VERSION ""

NS_ :

BS_:

BU_: AuxInput VT TECU TC Sprayer GPS

BO_ 2365458942 TFR: 8 Vector__XXX
 SG_ LimitStatusReporting : 27|1@1+ (1,0) [0|0] "" Vector__XXX
 SG_ SpeedInfo_EngineSpeed : 0|1@1+ (1,0) [0|1] "" Vector__XXX
 SG_ SpeedInfo_GroundBasedSpeed : 1|1@1+ (1,0) [0|1] "" Vector__XXX
 SG_ SpeedInfo_WheelBasedSpeed : 2|1@1+ (1,0) [0|1] "" Vector__XXX
 SG_ PowerMgt_MaintainPower : 3|1@1+ (1,0) [0|1] "" Vector__XXX
 SG_ PowerMgt_MaxTimeTractorPower : 4|1@1+ (1,0) [0|1] "" Vector__XXX
 SG_ PowerMgt_KeySwitch : 5|1@1+ (1,0) [0|1] "" Vector__XXX
 SG_ TractorClass : 6|2@1+ (1,0) [0|3] "" Vector__XXX
 SG_ LanguageCmdStorageInTractorECU : 10|1@1+ (1,0) [0|1] "" Vector__XXX
 SG_ Lighting_MinimalSet : 11|1@1+ (1,0) [0|1] "" Vector__XXX
 SG_ PTOInfo_RearShaftEngagement : 12|1@1+ (1,0) [0|0] "" Vector__XXX
 SG_ PTOInfo_RearShaftSpeed : 13|1@1+ (1,0) [0|1] "" Vector__XXX
 SG_ HitchInfo_RearInWork : 14|1@1+ (1,0) [0|1] "" Vector__XXX
 SG_ HitchInfo_RearPosition : 15|1@1+ (1,0) [0|1] "" Vector__XXX
 SG_ EstimatedOrMeasuredAuxValveState : 16|1@1+ (1,0) [0|1] "" Vector__XXX
 SG_ Light_FullImplLightingMessageSet : 17|1@1+ (1,0) [0|1] "" Vector__XXX
 SG_ AddHitchParameter_RearDraft : 18|1@1+ (1,0) [0|1] "" Vector__XXX
 SG_ SpeedAndDist_WheelBasedDirection : 19|1@1+ (1,0) [0|1] "" Vector__XXX
 SG_ SpeedAndDist_WheelBasedDistance : 20|1@1+ (1,0) [0|1] "" Vector__XXX
 SG_ SpeedAndDist_GndBasedDirection : 21|1@1+ (1,0) [0|1] "" Vector__XXX
 SG_ SpeedAndDist_GndBasedDistance : 22|1@1+ (1,0) [0|1] "" Vector__XXX
 SG_ TimeDate : 23|1@1+ (1,0) [0|1] "" Vector__XXX
 SG_ AuxiliaryValveCmd : 28|1@1+ (1,0) [0|1] "" Vector__XXX
 SG_ PTOCmd_RearPTOEngagementCmd : 29|1@1+ (1,0) [0|1] "" Vector__XXX
 SG_ PTOCmd_RearPTOSpeedCmd : 30|1@1+ (1,0) [0|1] "" Vector__XXX
 SG_ HitchCmd_RearHitchPosition : 31|1@1+ (1,0) [0|1] "" Vector__XXX
 SG_ NavigPseudorangeNoiseStatistic : 37|1@1+ (1,0) [0|1] "" Vector__XXX
 SG_ NavigSystemPositionData : 38|1@1+ (1,0) [0|1] "" Vector__XXX
 SG_ NavigSystemHighOutputPosition : 39|1@1+ (1,0) [0|1] "" Vector__XXX
 SG_ PTOCmd_FrontPTOEngagementCmd : 40|1@1+ (1,0) [0|1] "" Vector__XXX
 SG_ PTOCmd_FrontPTOSpeedCmd : 41|1@1+ (1,0) [0|1] "" Vector__XXX
 SG_ HitchCmd_FrontHitchPosition : 42|1@1+ (1,0) [0|1] "" Vector__XXX
 SG_ AddHitchParameter__FrontDraft : 43|1@1+ (1,0) [0|1] "" Vector__XXX
 SG_ PTOInfo_FrontShaftEngagement : 44|1@1+ (1,0) [0|1] "" Vector__XXX
 SG_ PTOInfo_FrontShaftSpeed : 45|1@1+ (1,0) [0|1] "" Vector__XXX
 SG_ HitchInfo_FrontInWork : 46|1@1+ (1,0) [0|1] "" Vector__XXX
 SG_ HitchInfo_FrontPosition : 47|1@1+ (1,0) [0|1] "" Vector__XXX

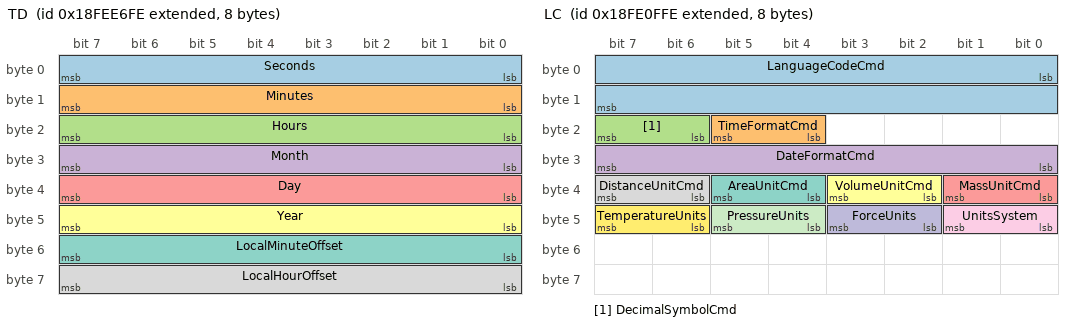
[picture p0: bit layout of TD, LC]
BO_ 2566842110 TD: 8 Vector__XXX
 SG_ Seconds : 0|8@1+ (0.25,0) [0|59.75] "s" Vector__XXX
 SG_ Minutes : 8|8@1+ (1,0) [0|59] "min" Vector__XXX
 SG_ Hours : 16|8@1+ (1,0) [0|23] "h" Vector__XXX
 SG_ Month : 24|8@1+ (1,0) [0|12] "month" Vector__XXX
 SG_ Day : 32|8@1+ (0.25,0) [0.25|31.75] "day" Vector__XXX
 SG_ Year : 40|8@1+ (1,1985) [1985|2235] "year" Vector__XXX
 SG_ LocalMinuteOffset : 48|8@1+ (1,0) [0|59] "min" Vector__XXX
 SG_ LocalHourOffset : 56|8@1+ (1,-125) [-149|-102] "" Vector__XXX

BO_ 2566787070 LC: 8 Vector__XXX
 SG_ LanguageCodeCmd : 0|16@1+ (1,0) [0|16383] "" Vector__XXX
 SG_ TimeFormatCmd : 20|2@1+ (1,0) [0|3] "" Vector__XXX
 SG_ DecimalSymbolCmd : 22|2@1+ (1,0) [0|3] "" Vector__XXX
 SG_ DateFormatCmd : 24|8@1+ (1,0) [0|255] "" Vector__XXX
 SG_ MassUnitCmd : 32|2@1+ (1,0) [0|3] "" Vector__XXX
 SG_ VolumeUnitCmd : 34|2@1+ (1,0) [0|3] "" Vector__XXX
 SG_ AreaUnitCmd : 36|2@1+ (1,0) [0|3] "" Vector__XXX
 SG_ DistanceUnitCmd : 38|2@1+ (1,0) [0|3] "" Vector__XXX
 SG_ UnitsSystem : 40|2@1+ (1,0) [0|3] "" Vector__XXX
 SG_ ForceUnits : 42|2@1+ (1,0) [0|3] "" Vector__XXX
 SG_ PressureUnits : 44|2@1+ (1,0) [0|3] "" Vector__XXX
 SG_ TemperatureUnits : 46|2@1+ (1,0) [0|3] "" Vector__XXX

BO_ 2566843646 VI: 200 Vector__XXX
 SG_ VehicleIdentificationNumber : 0|8@1+ (1,0) [0|255] "" Vector__XXX

BO_ 2362179200 PD_Sprayer: 8 Sprayer
 SG_ ErrorElementNumber m13 : 4|12@1+ (1,0) [0|4095] "" Vector__XXX
 SG_ ErrorDDI m13 : 16|16@1+ (1,0) [0|65535] "" Vector__XXX
 SG_ ErrorCodeProcessData6 m13 : 37|1@1+ (1,0) [0|1] "" Vector__XXX
 SG_ ErrorCodeProcessData5 m13 : 36|1@1+ (1,0) [0|1] "" Vector__XXX
 SG_ ErrorCodeProcessData4 m13 : 35|1@1+ (1,0) [0|1] "" Vector__XXX
 SG_ ErrorCodeProcessData3 m13 : 34|1@1+ (1,0) [0|1] "" Vector__XXX
 SG_ ErrorCodeProcessData2 m13 : 33|1@1+ (1,0) [0|1] "" Vector__XXX
 SG_ ErrorCodeProcessData1 m13 : 32|1@1+ (1,0) [0|1] "" Vector__XXX
 SG_ Status_TotalsActive m15 : 32|1@1+ (1,0) [0|1] "" Vector__XXX
 SG_ ExecutedCommand m14 : 48|8@1+ (1,0) [0|65535] "" Vector__XXX
 SG_ SourceAddressWSM m14 : 40|8@1+ (1,0) [0|65535] "" Vector__XXX
 SG_ StatusBusyExecuting m14 : 35|1@1+ (1,0) [0|1] "" Vector__XXX
 SG_ StatusBusyReading m14 : 34|1@1+ (1,0) [0|1] "" Vector__XXX
 SG_ StatusBusySaving m14 : 33|1@1+ (1,0) [0|1] "" Vector__XXX
 SG_ StatusTotalsActive m14 : 32|1@1+ (1,0) [0|1] "" Vector__XXX
 SG_ ObjectIdChanged m13 : 8|16@1+ (1,0) [0|65535] "" Vector__XXX
 SG_ DesignatorLength m12 : 24|8@1+ (1,0) [0|255] "bytes" Vector__XXX
 SG_ ObjectIdToChange m12 : 8|16@1+ (1,0) [0|65535] "" Vector__XXX
 SG_ ErrorCodeChangeDesignator m13 : 24|8@1+ (1,0) [0|0] "" Vector__XXX
 SG_ ErrorCodeObjectPoolDelete m11 : 8|8@1+ (1,0) [0|0] "" Vector__XXX
 SG_ ErrorCodeObjPool4 m9 : 51|1@1+ (1,0) [0|0] "" Vector__XXX
 SG_ ErrorCodeObjPool3 m9 : 50|1@1+ (1,0) [0|0] "" Vector__XXX
 SG_ ErrorCodeObjPool2 m9 : 49|1@1+ (1,0) [0|0] "" Vector__XXX
 SG_ ErrorCodeObjPool1 m9 : 48|1@1+ (1,0) [0|0] "" Vector__XXX
 SG_ ErrorCodeObjPoolActiveResp3 m9 : 10|1@1+ (1,0) [0|0] "" Vector__XXX
 SG_ ErrorCodeObjPoolActiveResp2 m9 : 9|1@1+ (1,0) [0|0] "" Vector__XXX
 SG_ ErrorCodeObjPoolActiveResp1 m9 : 8|1@1+ (1,0) [0|0] "" Vector__XXX
 SG_ ObjectIdOfFaultyObject m9 : 32|16@1+ (1,0) [0|65535] "" Vector__XXX
 SG_ ParentObjectIdOfFaultyObject m9 : 16|16@1+ (1,0) [0|65535] "" Vector__XXX
 SG_ ReceivedDataSize m7 : 16|32@1+ (1,0) [0|4294967295] "bytes" Vector__XXX
 SG_ ErrorCodeObjPoolTransfer m7 : 8|8@1+ (1,0) [0|3] "" Vector__XXX
 SG_ Status m5 : 8|8@1+ (1,0) [0|1] "" Vector__XXX
 SG_ RequestTransferDataSize m4 : 8|32@1+ (1,0) [0|4294967295] "bytes" Vector__XXX
 SG_ TemperatureUnits m2 : 54|2@1+ (1,0) [0|3] "" Vector__XXX
 SG_ PressureUnits m2 : 52|2@1+ (1,0) [0|3] "" Vector__XXX
 SG_ ForceUnits m2 : 50|2@1+ (1,0) [0|3] "" Vector__XXX
 SG_ UnitsSystem m2 : 48|2@1+ (1,0) [0|3] "" Vector__XXX
 SG_ DistanceUnitCmd m2 : 46|2@1+ (1,0) [0|3] "" Vector__XXX
 SG_ AreaUnitCmd m2 : 44|2@1+ (1,0) [0|3] "" Vector__XXX
 SG_ VolumeUnitCmd m2 : 42|2@1+ (1,0) [0|3] "" Vector__XXX
 SG_ MassUnitCmd m2 : 40|2@1+ (1,0) [0|3] "" Vector__XXX
 SG_ DateFormatCmd m2 : 32|8@1+ (1,0) [0|255] "" Vector__XXX
 SG_ DecimalSymbolCmd m2 : 30|2@1+ (1,0) [0|3] "" Vector__XXX
 SG_ TimeFormatCmd m2 : 28|2@1+ (1,0) [0|3] "" Vector__XXX
 SG_ LanguageCodeCmd m2 : 8|16@1+ (1,0) [0|16383] "" Vector__XXX
 SG_ StructureLabel m1 : 8|56@1+ (1,0) [0|0] "" Vector__XXX
 SG_ DeviceDescriptionMsgType m1M : 4|4@1+ (1,0) [0|15] "" Vector__XXX
 SG_ VersionNumberISO11783Part10 m1 : 8|8@1- (1,0) [0|255] "" Vector__XXX
 SG_ TechnicalDataMsgType m0M : 4|4@1+ (1,0) [0|15] "" Vector__XXX
 SG_ Command M : 0|4@1+ (1,0) [0|15] "" Vector__XXX
 SG_ ElementNumber m2 : 4|12@1+ (1,0) [0|4095] "" Vector__XXX
 SG_ DDI m2M : 16|16@1+ (1,0) [0|65535] "" Vector__XXX
 SG_ MinMassPerAreaAppRate m152 : 32|32@1- (0.01,0) [0|2147480000] "mm³/m³" Vector__XXX
 SG_ DataDictionaryVersion m0 : 32|32@1- (1,0) [0|21474800] "" Vector__XXX
 SG_ RequestDefaultProcessData m57343 : 32|32@1- (1,0) [0|0] "" Vector__XXX
 SG_ AreaPerTimeCapacity m151 : 32|32@1- (1,0) [0|2147483647] "mm²/s" Vector__XXX
 SG_ FuelConsumptionPerArea m150 : 32|32@1- (1,0) [0|2147483647] "mm³/ m²" Vector__XXX
 SG_ FuelConsumptionPerTime m149 : 32|32@1- (1,0) [0|2147483647] "mm³/s" Vector__XXX
 SG_ TotalFuelConsumption m148 : 32|32@1- (1,0) [0|2147483647] "ml" Vector__XXX
 SG_ LogCount m147 : 32|32@1- (1,0) [0|2147483647] "" Vector__XXX
 SG_ PitchAngle m146 : 32|32@1- (0.001,0) [-180|180] "°" Vector__XXX
 SG_ RollAngle m145 : 32|32@1- (0.001,0) [-180|180] "°" Vector__XXX
 SG_ YawAngle m144 : 32|32@1- (0.001,0) [-180|180] "°" Vector__XXX
 SG_ ActualValueTimeLatency m143 : 32|32@1- (1,0) [-2147483647|2147483647] "ms" Vector__XXX
 SG_ SetpointTimeLatency m142 : 32|32@1- (1,0) [-2147483647|2147483647] "ms" Vector__XXX
 SG_ WorkState m141 : 32|32@1- (1,0) [0|3] "" Vector__XXX
 SG_ PercentageAppRateSetpoint m140 : 32|32@1- (1,0) [0|2147483647] "ppm" Vector__XXX
 SG_ DeviceCountCapacity m139 : 32|32@1- (1,0) [0|2147483647] "" Vector__XXX
 SG_ DeviceMassCapacity m138 : 32|32@1- (1,0) [0|2147483647] "g" Vector__XXX
 SG_ DeviceVolumeCapacity m137 : 32|32@1- (1,0) [0|2147483647] "ml" Vector__XXX
 SG_ DeviceElementOffsetZ m136 : 32|32@1- (1,0) [-2147483647|2147483647] "mm" Vector__XXX
 SG_ DeviceElementOffsetY m135 : 32|32@1- (1,0) [-2147483647|2147483647] "mm" Vector__XXX
 SG_ DeviceElementOffsetX m134 : 32|32@1- (1,0) [-2147483647|2147483647] "mm" Vector__XXX
 SG_ AuxiliaryValveInvertPorts m133 : 32|32@1- (1,0) [-2147480000|2147480000] "" Vector__XXX
 SG_ AuxiliaryValveProgressivRetract m132 : 32|32@1- (1,0) [-2147480000|2147480000] "" Vector__XXX
 SG_ AuxiliaryValveProgressivExtend m131 : 32|32@1- (1,0) [-2147483647|2147483647] "" Vector__XXX
 SG_ AuxiliaryValveFloatThreshold m130 : 32|32@1- (0.1,0) [-214748367.9|214748367.9] "%" Vector__XXX
 SG_ AuxiliaryValveRampRetractDown m129 : 32|32@1- (1,0) [-2147483647|2147483647] "ms" Vector__XXX
 SG_ AuxiliaryValveRampRetractUp m128 : 32|32@1- (1,0) [-2147483647|2147483647] "ms" Vector__XXX
 SG_ AuxiliaryValveRampExtendDown m127 : 32|32@1- (1,0) [-2147483647|2147483647] "ms" Vector__XXX
 SG_ AuxiliaryValveScalingRetract m125 : 32|32@1- (0.1,0) [-214748367.9|214748367.9] "%" Vector__XXX
 SG_ AuxiliaryValveScalingExtend m124 : 32|32@1- (0.1,0) [-214748367.9|214748367.9] "%" Vector__XXX
 SG_ AuxiliaryRampExtendUp m126 : 32|32@1- (1,0) [-2147483647|2147483647] "ms" Vector__XXX
 SG_ AppRateVolumePerArea_Set m1 : 32|32@1- (0.01,0) [0|21474836.47] "mm³/m²" Vector__XXX
 SG_ AppRateVolumePerArea_Act m2 : 32|32@1- (0.01,0) [0|21474836.47] "mm³/m²" Vector__XXX
 SG_ AppRateVolumePerArea_Def m3 : 32|32@1- (0.01,0) [0|21474836.47] "mm³/m²" Vector__XXX
 SG_ AppRateVolumePerArea_Min m4 : 32|32@1- (0.01,0) [0|21474836.47] "mm³/m²" Vector__XXX
 SG_ AppRateVolumePerArea_Max m5 : 32|32@1- (0.01,0) [0|21474836.47] "mm³/m²" Vector__XXX
 SG_ AppRateMassPerArea_Set m6 : 32|32@1- (1,0) [0|2147483647] "mg/m²" Vector__XXX
 SG_ AppRateMassPerArea_Act m7 : 32|32@1- (1,0) [0|2147483647] "mg/m²" Vector__XXX
 SG_ AppRateMassPerArea_Def m8 : 32|32@1- (1,0) [0|2147483647] "mg/m²" Vector__XXX
 SG_ AppRateMassPerArea_Min m9 : 32|32@1- (1,0) [0|2147483647] "mg/m²" Vector__XXX
 SG_ AppRateMassPerArea_Max m10 : 32|32@1- (1,0) [0|2147483647] "mg/m²" Vector__XXX
 SG_ AppRateCountPerArea_Set m11 : 32|32@1- (0.001,0) [0|2147483.647] "1/m²" Vector__XXX
 SG_ AppRateCountPerArea_Act m12 : 32|32@1- (0.001,0) [0|2147483.647] "1/m²" Vector__XXX
 SG_ AppRateCountPerArea_Def m13 : 32|32@1- (0.001,0) [0|2147483.647] "1/m²" Vector__XXX
 SG_ AppRateCountPerArea_Min m14 : 32|32@1- (0.001,0) [0|2147483.647] "1/m²" Vector__XXX
 SG_ AppRateCountPerArea_Max m15 : 32|32@1- (0.001,0) [0|2147483.647] "1/m²" Vector__XXX
 SG_ SetAppRateDistance_Set m16 : 32|32@1- (1,0) [0|2147483647] "mm" Vector__XXX
 SG_ AppRateDistance_Act m17 : 32|32@1- (1,0) [0|2147483647] "mm" Vector__XXX
 SG_ AppRateDistance_Def m18 : 32|32@1- (1,0) [0|2147483647] "mm" Vector__XXX
 SG_ AppRateDistance_Min m19 : 32|32@1- (1,0) [0|2147483647] "mm" Vector__XXX
 SG_ AppRateDistance_Max m20 : 32|32@1- (1,0) [0|2147483647] "mm" Vector__XXX
 SG_ AppRateVolumePerVolume_Set m21 : 32|32@1- (1,0) [0|2147483647] "mm³/m³" Vector__XXX
 SG_ AppRateVolumePerVolume_Act m22 : 32|32@1- (1,0) [0|2147483647] "mm³/m³" Vector__XXX
 SG_ AppRateVolumePerVolume_Def m23 : 32|32@1- (1,0) [0|2147483647] "mm³/m³" Vector__XXX
 SG_ AppRateVolumePerVolume_Min m24 : 32|32@1- (1,0) [0|2147483647] "mm³/m³" Vector__XXX
 SG_ AppRateVolumePerVolume_Max m25 : 32|32@1- (1,0) [0|2147483647] "mm³/m³" Vector__XXX
 SG_ AppRateMassPerMass_Set m26 : 32|32@1- (1,0) [0|2147483647] "mg/kg" Vector__XXX
 SG_ AppRateMassPerMass_Act m27 : 32|32@1- (1,0) [0|2147483647] "mg/kg" Vector__XXX
 SG_ AppRateMassPerMass_Def m28 : 32|32@1- (1,0) [0|2147483647] "mg/kg" Vector__XXX
 SG_ AppRateMassPerMass_Min m29 : 32|32@1- (1,0) [0|2147483647] "mg/kg" Vector__XXX
 SG_ AppRateMassPerMass_Max m30 : 32|32@1- (1,0) [0|2147483647] "mg/kg" Vector__XXX
 SG_ AppRateVolumePerMass_Set m31 : 32|32@1- (1,0) [0|2147483647] "mm³/kg" Vector__XXX
 SG_ AppRateVolumePerMass_Act m32 : 32|32@1- (1,0) [0|2147483647] "mm³/kg" Vector__XXX
 SG_ AppRateVolumePerMass_Def m33 : 32|32@1- (1,0) [0|2147483647] "mm³/kg" Vector__XXX
 SG_ AppRateVolumePerMass_Min m34 : 32|32@1- (1,0) [0|2147483647] "mm³/kg" Vector__XXX
 SG_ AppRateVolumePerMass_Max m35 : 32|32@1- (1,0) [0|2147483647] "mm³/kg" Vector__XXX
 SG_ AppRateVolumePerTime_Set m36 : 32|32@1- (1,0) [0|2147483647] "mm³/s" Vector__XXX
 SG_ AppRateVolumePerTime_Act m37 : 32|32@1- (1,0) [0|2147483647] "mm³/s" Vector__XXX
 SG_ AppRateVolumePerTime_Def m38 : 32|32@1- (1,0) [0|2147483647] "mm³/s" Vector__XXX
 SG_ AppRateVolumePerTime_Min m39 : 32|32@1- (1,0) [0|2147483647] "mm³/s" Vector__XXX
 SG_ AppRateVolumePerTime_Max m40 : 32|32@1- (1,0) [0|2147483647] "mm³/s" Vector__XXX
 SG_ AppRateMassPerTime_Set m41 : 32|32@1- (1,0) [0|2147483647] "mg/s" Vector__XXX
 SG_ AppRateMassPerTime_Act m42 : 32|32@1- (1,0) [0|2147483647] "mg/s" Vector__XXX
 SG_ AppRateMassPerTime_Def m43 : 32|32@1- (1,0) [0|2147483647] "mg/s" Vector__XXX
 SG_ AppRateMassPerTime_Min m44 : 32|32@1- (1,0) [0|2147483647] "mg/s" Vector__XXX
 SG_ AppRateMassPerTime_Max m45 : 32|32@1- (1,0) [0|2147483647] "mg/s" Vector__XXX
 SG_ AppRateCountPerTime_Set m46 : 32|32@1- (0.001,0) [0|2147483.647] "1/s" Vector__XXX
 SG_ AppRateCountPerTime_Act m47 : 32|32@1- (0.001,0) [0|2147483.647] "1/s" Vector__XXX
 SG_ AppRateCountPerTime_Def m48 : 32|32@1- (0.001,0) [0|2147483.647] "1/s" Vector__XXX
 SG_ AppRateCountPerTime_Min m49 : 32|32@1- (0.001,0) [0|2147483.647] "1/s" Vector__XXX
 SG_ AppRateCountPerTime_Max m50 : 32|32@1- (0.001,0) [0|2147483.647] "1/s" Vector__XXX
 SG_ SetTillageDepth_Set m51 : 32|32@1- (1,0) [0|2147483647] "mm" Vector__XXX
 SG_ TillageDepth_Act m52 : 32|32@1- (1,0) [0|2147483647] "mm" Vector__XXX
 SG_ TillageDepth_Def m53 : 32|32@1- (1,0) [0|2147483647] "mm" Vector__XXX
 SG_ TillageDepth_Min m54 : 32|32@1- (1,0) [0|2147483647] "mm" Vector__XXX
 SG_ TillageDepth_Max m55 : 32|32@1- (1,0) [0|2147483647] "mm" Vector__XXX
 SG_ SeedingDeph_Set m56 : 32|32@1- (1,0) [0|2147483647] "mm" Vector__XXX
 SG_ SeedingDeph_Act m57 : 32|32@1- (1,0) [0|2147483647] "mm" Vector__XXX
 SG_ SeedingDeph_Def m58 : 32|32@1- (1,0) [0|2147483647] "mm" Vector__XXX
 SG_ SeedingDeph_Min m59 : 32|32@1- (1,0) [0|2147483647] "mm" Vector__XXX
 SG_ SeedingDeph_Max m60 : 32|32@1- (1,0) [0|2147483647] "mm" Vector__XXX
 SG_ WorkingHeight_Set m61 : 32|32@1- (1,0) [0|2147483647] "mm" Vector__XXX
 SG_ WorkingHeight_Act m62 : 32|32@1- (1,0) [0|2147483647] "mm" Vector__XXX
 SG_ WorkingHeight_Def m63 : 32|32@1- (1,0) [0|2147483647] "mm" Vector__XXX
 SG_ WorkingHeight_Min m64 : 32|32@1- (1,0) [0|2147483647] "mm" Vector__XXX
 SG_ WorkingHeight_Max m65 : 32|32@1- (1,0) [0|2147483647] "mm" Vector__XXX
 SG_ WorkingWidth_Set m66 : 32|32@1- (1,0) [0|2147483647] "mm" Vector__XXX
 SG_ WorkingWidth_Act m67 : 32|32@1- (1,0) [0|2147483647] "mm" Vector__XXX
 SG_ WorkingWidth_Def m68 : 32|32@1- (1,0) [0|2147483647] "mm" Vector__XXX
 SG_ WorkingWidth_Min m69 : 32|32@1- (1,0) [0|2147483647] "mm" Vector__XXX
 SG_ WorkingWidth_Max m70 : 32|32@1- (1,0) [0|2147483647] "mm" Vector__XXX
 SG_ ContentAsVolume_Set m71 : 32|32@1- (1,0) [0|2147483647] "ml" Vector__XXX
 SG_ ContentAsVolume_Act m72 : 32|32@1- (1,0) [0|2147483647] "ml" Vector__XXX
 SG_ ContentAsVolume_Max m73 : 32|32@1- (1,0) [0|2147483647] "ml" Vector__XXX
 SG_ ContentAsMass_Set m74 : 32|32@1- (1,0) [0|2147483647] "g" Vector__XXX
 SG_ ContentAsMass_Act m75 : 32|32@1- (1,0) [0|2147483647] "g" Vector__XXX
 SG_ ContentAsMass_Max m76 : 32|32@1- (1,0) [0|2147483647] "g" Vector__XXX
 SG_ ContentAsCount_Set m77 : 32|32@1- (1,0) [0|2147483647] "" Vector__XXX
 SG_ ContentAsCount_Act m78 : 32|32@1- (1,0) [0|2147483647] "" Vector__XXX
 SG_ ContentAsCount_Max m79 : 32|32@1- (1,0) [0|2147483647] "" Vector__XXX
 SG_ AccumulatedAppAsVolume m80 : 32|32@1- (1,0) [0|2147483647] "l" Vector__XXX
 SG_ AccumulatedAppAsMass m81 : 32|32@1- (1,0) [0|2147483647] "kg" Vector__XXX
 SG_ AccumulatedAppAsCount m82 : 32|32@1- (1,0) [0|2147483647] "" Vector__XXX
 SG_ YieldVolumePerArea m83 : 32|32@1- (1,0) [0|2147483647] "ml/m²" Vector__XXX
 SG_ YieldMassPerArea m84 : 32|32@1- (1,0) [0|2147483647] "mg/m²" Vector__XXX
 SG_ YieldCountPerArea m85 : 32|32@1- (0.001,0) [0|2147483.647] "1/m²" Vector__XXX
 SG_ YieldVolumePerTime m86 : 32|32@1- (1,0) [0|2147483647] "ml/s" Vector__XXX
 SG_ YieldMassPerTime m87 : 32|32@1- (1,0) [0|2147483647] "mg/s" Vector__XXX
 SG_ YieldCountPerTime m88 : 32|32@1- (0.001,0) [0|2147483.647] "1/s" Vector__XXX
 SG_ AccumulatedYieldAsVolume m89 : 32|32@1- (1,0) [0|2147483647] "ml" Vector__XXX
 SG_ AccumulatedYieldAsMass m90 : 32|32@1- (1,0) [0|2147483647] "g" Vector__XXX
 SG_ AccumulatedYieldAsCount m91 : 32|32@1- (1,0) [0|2147483647] "" Vector__XXX
 SG_ CropYieldLossVolumePerArea m92 : 32|32@1- (1,0) [0|2147483647] "ml/m²" Vector__XXX
 SG_ CropYieldLossMassPerArea m93 : 32|32@1- (1,0) [0|2147483647] "mg/m²" Vector__XXX
 SG_ CropYieldLossCountPerArea m94 : 32|32@1- (0.001,0) [0|2147483.647] "1/m²" Vector__XXX
 SG_ CropYieldLossVolumePerTime m95 : 32|32@1- (1,0) [0|2147483647] "ml/s" Vector__XXX
 SG_ CropYieldLossMassPerTime m96 : 32|32@1- (1,0) [0|2147483647] "mg/s" Vector__XXX
 SG_ CropYieldLossCountPerTime m97 : 32|32@1- (0.001,0) [0|2147483.647] "1/s" Vector__XXX
 SG_ CropYieldLoss m98 : 32|32@1- (1,0) [0|2147483647] "ppm" Vector__XXX
 SG_ MoistureInCropYield m99 : 32|32@1- (1,0) [0|2147483647] "ppm" Vector__XXX
 SG_ DirtMaterialInCropYield m100 : 32|32@1- (1,0) [0|2147483647] "ppm" Vector__XXX
 SG_ BaleWidth_Set m101 : 32|32@1- (1,0) [0|2147483647] "mm" Vector__XXX
 SG_ BaleWidth_Act m102 : 32|32@1- (1,0) [0|2147483647] "mm" Vector__XXX
 SG_ BaleWidth_Def m103 : 32|32@1- (1,0) [0|2147483647] "mm" Vector__XXX
 SG_ BaleWidth_Min m104 : 32|32@1- (1,0) [0|2147483647] "mm" Vector__XXX
 SG_ BaleWidth_Max m105 : 32|32@1- (1,0) [0|2147483647] "mm" Vector__XXX
 SG_ BaleHeight_Set m106 : 32|32@1- (1,0) [0|2147483647] "mm" Vector__XXX
 SG_ BaleHeight_Act m107 : 32|32@1- (1,0) [0|2147483647] "mm" Vector__XXX
 SG_ BaleHeight_Def m108 : 32|32@1- (1,0) [0|2147483647] "mm" Vector__XXX
 SG_ BaleHeight_Min m109 : 32|32@1- (1,0) [0|2147483647] "mm" Vector__XXX
 SG_ BaleHeight_Max m110 : 32|32@1- (1,0) [0|2147483647] "mm" Vector__XXX
 SG_ BaleSize_Set m111 : 32|32@1- (1,0) [0|2147483647] "mm" Vector__XXX
 SG_ BaleSize_Act m112 : 32|32@1- (1,0) [0|2147483647] "mm" Vector__XXX
 SG_ BaleSize_Def m113 : 32|32@1- (1,0) [0|2147483647] "mm" Vector__XXX
 SG_ BaleSize_Min m114 : 32|32@1- (1,0) [0|2147483647] "mm" Vector__XXX
 SG_ BaleSize_Max m115 : 32|32@1- (1,0) [0|2147483647] "mm" Vector__XXX
 SG_ AccumulatedArea m116 : 32|32@1- (1,0) [0|2147483647] "m²" Vector__XXX
 SG_ AccumulatedDistanceInWork m117 : 32|32@1- (1,0) [0|2147483647] "mm" Vector__XXX
 SG_ AccumulatedDistanceOutWork m118 : 32|32@1- (1,0) [0|2147483647] "mm" Vector__XXX
 SG_ AccumulatedTimeInWork m119 : 32|32@1- (1,0) [0|2147483647] "s" Vector__XXX
 SG_ AccumulatedTimeOutWork m120 : 32|32@1- (1,0) [0|2147483647] "s" Vector__XXX
 SG_ PrdoucDensityMassPerArea m121 : 32|32@1- (1,0) [0|2147483647] "g/l" Vector__XXX
 SG_ PrdoucDensityMassPerCount m122 : 32|32@1- (1,0) [0|2147483647] "mg/1000" Vector__XXX
 SG_ PrdoucDensityVolumePerCount m123 : 32|32@1- (1,0) [0|2147483647] "ml/1000" Vector__XXX

BO_ 2362179319 PD_TC: 8 Vector__XXX
 SG_ ErrorElementNumber m13 : 4|12@1+ (1,0) [0|4095] "" Vector__XXX
 SG_ ErrorDDI m13 : 16|16@1+ (1,0) [0|65535] "" Vector__XXX
 SG_ ErrorCodeProcessData6 m13 : 37|1@1+ (1,0) [0|1] "" Vector__XXX
 SG_ ErrorCodeProcessData5 m13 : 36|1@1+ (1,0) [0|1] "" Vector__XXX
 SG_ ErrorCodeProcessData4 m13 : 35|1@1+ (1,0) [0|1] "" Vector__XXX
 SG_ ErrorCodeProcessData3 m13 : 34|1@1+ (1,0) [0|1] "" Vector__XXX
 SG_ ErrorCodeProcessData2 m13 : 33|1@1+ (1,0) [0|1] "" Vector__XXX
 SG_ ErrorCodeProcessData1 m13 : 32|1@1+ (1,0) [0|1] "" Vector__XXX
 SG_ Status_TotalsActive m15 : 32|1@1+ (1,0) [0|1] "" Vector__XXX
 SG_ ExecutedCommand m14 : 48|8@1+ (1,0) [0|65535] "" Vector__XXX
 SG_ SourceAddressWSM m14 : 40|8@1+ (1,0) [0|65535] "" Vector__XXX
 SG_ StatusBusyExecuting m14 : 35|1@1+ (1,0) [0|1] "" Vector__XXX
 SG_ StatusBusyReading m14 : 34|1@1+ (1,0) [0|1] "" Vector__XXX
 SG_ StatusBusySaving m14 : 33|1@1+ (1,0) [0|1] "" Vector__XXX
 SG_ StatusTotalsActive m14 : 32|1@1+ (1,0) [0|1] "" Vector__XXX
 SG_ ObjectIdChanged m13 : 8|16@1+ (1,0) [0|65535] "" Vector__XXX
 SG_ DesignatorLength m12 : 24|8@1+ (1,0) [0|255] "bytes" Vector__XXX
 SG_ ObjectIdToChange m12 : 8|16@1+ (1,0) [0|65535] "" Vector__XXX
 SG_ ErrorCodeChangeDesignator m13 : 24|8@1+ (1,0) [0|0] "" Vector__XXX
 SG_ ErrorCodeObjectPoolDelete m11 : 8|8@1+ (1,0) [0|0] "" Vector__XXX
 SG_ ErrorCodeObjPool4 m9 : 51|1@1+ (1,0) [0|0] "" Vector__XXX
 SG_ ErrorCodeObjPool3 m9 : 50|1@1+ (1,0) [0|0] "" Vector__XXX
 SG_ ErrorCodeObjPool2 m9 : 49|1@1+ (1,0) [0|0] "" Vector__XXX
 SG_ ErrorCodeObjPool1 m9 : 48|1@1+ (1,0) [0|0] "" Vector__XXX
 SG_ ErrorCodeObjPoolActiveResp3 m9 : 10|1@1+ (1,0) [0|0] "" Vector__XXX
 SG_ ErrorCodeObjPoolActiveResp2 m9 : 9|1@1+ (1,0) [0|0] "" Vector__XXX
 SG_ ErrorCodeObjPoolActiveResp1 m9 : 8|1@1+ (1,0) [0|0] "" Vector__XXX
 SG_ ObjectIdOfFaultyObject m9 : 32|16@1+ (1,0) [0|65535] "" Vector__XXX
 SG_ ParentObjectIdOfFaultyObject m9 : 16|16@1+ (1,0) [0|65535] "" Vector__XXX
 SG_ ReceivedDataSize m7 : 16|32@1+ (1,0) [0|4294967295] "bytes" Vector__XXX
 SG_ ErrorCodeObjPoolTransfer m7 : 8|8@1+ (1,0) [0|3] "" Vector__XXX
 SG_ Status m5 : 8|8@1+ (1,0) [0|1] "" Vector__XXX
 SG_ RequestTransferDataSize m4 : 8|32@1+ (1,0) [0|4294967295] "bytes" Vector__XXX
 SG_ TemperatureUnits m2 : 54|2@1+ (1,0) [0|3] "" Vector__XXX
 SG_ PressureUnits m2 : 52|2@1+ (1,0) [0|3] "" Vector__XXX
 SG_ ForceUnits m2 : 50|2@1+ (1,0) [0|3] "" Vector__XXX
 SG_ UnitsSystem m2 : 48|2@1+ (1,0) [0|3] "" Vector__XXX
 SG_ DistanceUnitCmd m2 : 46|2@1+ (1,0) [0|3] "" Vector__XXX
 SG_ AreaUnitCmd m2 : 44|2@1+ (1,0) [0|3] "" Vector__XXX
 SG_ VolumeUnitCmd m2 : 42|2@1+ (1,0) [0|3] "" Vector__XXX
 SG_ MassUnitCmd m2 : 40|2@1+ (1,0) [0|3] "" Vector__XXX
 SG_ DateFormatCmd m2 : 32|8@1+ (1,0) [0|255] "" Vector__XXX
 SG_ DecimalSymbolCmd m2 : 30|2@1+ (1,0) [0|3] "" Vector__XXX
 SG_ TimeFormatCmd m2 : 28|2@1+ (1,0) [0|3] "" Vector__XXX
 SG_ LanguageCodeCmd m2 : 8|16@1+ (1,0) [0|16383] "" Vector__XXX
 SG_ StructureLabel m1 : 8|56@1+ (1,0) [0|0] "" Vector__XXX
 SG_ DeviceDescriptionMsgType m1M : 4|4@1+ (1,0) [0|15] "" Vector__XXX
 SG_ VersionNumberISO11783Part10 m1 : 8|8@1- (1,0) [0|255] "" Vector__XXX
 SG_ TechnicalDataMsgType m0M : 4|4@1+ (1,0) [0|15] "" Vector__XXX
 SG_ Command M : 0|4@1+ (1,0) [0|15] "" Vector__XXX
 SG_ ElementNumber m2 : 4|12@1+ (1,0) [0|4095] "" Vector__XXX
 SG_ DDI m2M : 16|16@1+ (1,0) [0|65535] "" Vector__XXX
 SG_ MinMassPerAreaAppRate m152 : 32|32@1- (0.01,0) [0|2147480000] "mm³/m³" Vector__XXX
 SG_ DataDictionaryVersion m0 : 32|32@1- (1,0) [0|21474800] "" Vector__XXX
 SG_ RequestDefaultProcessData m57343 : 32|32@1- (1,0) [0|0] "" Vector__XXX
 SG_ AreaPerTimeCapacity m151 : 32|32@1- (1,0) [0|2147483647] "mm²/s" Vector__XXX
 SG_ FuelConsumptionPerArea m150 : 32|32@1- (1,0) [0|2147483647] "mm³/ m²" Vector__XXX
 SG_ FuelConsumptionPerTime m149 : 32|32@1- (1,0) [0|2147483647] "mm³/s" Vector__XXX
 SG_ TotalFuelConsumption m148 : 32|32@1- (1,0) [0|2147483647] "ml" Vector__XXX
 SG_ LogCount m147 : 32|32@1- (1,0) [0|2147483647] "" Vector__XXX
 SG_ PitchAngle m146 : 32|32@1- (0.001,0) [-180|180] "°" Vector__XXX
 SG_ RollAngle m145 : 32|32@1- (0.001,0) [-180|180] "°" Vector__XXX
 SG_ YawAngle m144 : 32|32@1- (0.001,0) [-180|180] "°" Vector__XXX
 SG_ ActualValueTimeLatency m143 : 32|32@1- (1,0) [-2147483647|2147483647] "ms" Vector__XXX
 SG_ SetpointTimeLatency m142 : 32|32@1- (1,0) [-2147483647|2147483647] "ms" Vector__XXX
 SG_ WorkState m141 : 32|32@1- (1,0) [0|3] "" Vector__XXX
 SG_ PercentageAppRateSetpoint m140 : 32|32@1- (1,0) [0|2147483647] "ppm" Vector__XXX
 SG_ DeviceCountCapacity m139 : 32|32@1- (1,0) [0|2147483647] "" Vector__XXX
 SG_ DeviceMassCapacity m138 : 32|32@1- (1,0) [0|2147483647] "g" Vector__XXX
 SG_ DeviceVolumeCapacity m137 : 32|32@1- (1,0) [0|2147483647] "ml" Vector__XXX
 SG_ DeviceElementOffsetZ m136 : 32|32@1- (1,0) [-2147483647|2147483647] "mm" Vector__XXX
 SG_ DeviceElementOffsetY m135 : 32|32@1- (1,0) [-2147483647|2147483647] "mm" Vector__XXX
 SG_ DeviceElementOffsetX m134 : 32|32@1- (1,0) [-2147483647|2147483647] "mm" Vector__XXX
 SG_ AuxiliaryValveInvertPorts m133 : 32|32@1- (1,0) [-2147480000|2147480000] "" Vector__XXX
 SG_ AuxiliaryValveProgressivRetract m132 : 32|32@1- (1,0) [-2147480000|2147480000] "" Vector__XXX
 SG_ AuxiliaryValveProgressivExtend m131 : 32|32@1- (1,0) [-2147483647|2147483647] "" Vector__XXX
 SG_ AuxiliaryValveFloatThreshold m130 : 32|32@1- (0.1,0) [-214748367.9|214748367.9] "%" Vector__XXX
 SG_ AuxiliaryValveRampRetractDown m129 : 32|32@1- (1,0) [-2147483647|2147483647] "ms" Vector__XXX
 SG_ AuxiliaryValveRampRetractUp m128 : 32|32@1- (1,0) [-2147483647|2147483647] "ms" Vector__XXX
 SG_ AuxiliaryValveRampExtendDown m127 : 32|32@1- (1,0) [-2147483647|2147483647] "ms" Vector__XXX
 SG_ AuxiliaryValveScalingRetract m125 : 32|32@1- (0.1,0) [-214748367.9|214748367.9] "%" Vector__XXX
 SG_ AuxiliaryValveScalingExtend m124 : 32|32@1- (0.1,0) [-214748367.9|214748367.9] "%" Vector__XXX
 SG_ AuxiliaryRampExtendUp m126 : 32|32@1- (1,0) [-2147483647|2147483647] "ms" Vector__XXX
 SG_ AppRateVolumePerArea_Set m1 : 32|32@1- (0.01,0) [0|21474836.47] "mm³/m²" Vector__XXX
 SG_ AppRateVolumePerArea_Act m2 : 32|32@1- (0.01,0) [0|21474836.47] "mm³/m²" Vector__XXX
 SG_ AppRateVolumePerArea_Def m3 : 32|32@1- (0.01,0) [0|21474836.47] "mm³/m²" Vector__XXX
 SG_ AppRateVolumePerArea_Min m4 : 32|32@1- (0.01,0) [0|21474836.47] "mm³/m²" Vector__XXX
 SG_ AppRateVolumePerArea_Max m5 : 32|32@1- (0.01,0) [0|21474836.47] "mm³/m²" Vector__XXX
 SG_ AppRateMassPerArea_Set m6 : 32|32@1- (1,0) [0|2147483647] "mg/m²" Vector__XXX
 SG_ AppRateMassPerArea_Act m7 : 32|32@1- (1,0) [0|2147483647] "mg/m²" Vector__XXX
 SG_ AppRateMassPerArea_Def m8 : 32|32@1- (1,0) [0|2147483647] "mg/m²" Vector__XXX
 SG_ AppRateMassPerArea_Min m9 : 32|32@1- (1,0) [0|2147483647] "mg/m²" Vector__XXX
 SG_ AppRateMassPerArea_Max m10 : 32|32@1- (1,0) [0|2147483647] "mg/m²" Vector__XXX
 SG_ AppRateCountPerArea_Set m11 : 32|32@1- (0.001,0) [0|2147483.647] "1/m²" Vector__XXX
 SG_ AppRateCountPerArea_Act m12 : 32|32@1- (0.001,0) [0|2147483.647] "1/m²" Vector__XXX
 SG_ AppRateCountPerArea_Def m13 : 32|32@1- (0.001,0) [0|2147483.647] "1/m²" Vector__XXX
 SG_ AppRateCountPerArea_Min m14 : 32|32@1- (0.001,0) [0|2147483.647] "1/m²" Vector__XXX
 SG_ AppRateCountPerArea_Max m15 : 32|32@1- (0.001,0) [0|2147483.647] "1/m²" Vector__XXX
 SG_ SetAppRateDistance_Set m16 : 32|32@1- (1,0) [0|2147483647] "mm" Vector__XXX
 SG_ AppRateDistance_Act m17 : 32|32@1- (1,0) [0|2147483647] "mm" Vector__XXX
 SG_ AppRateDistance_Def m18 : 32|32@1- (1,0) [0|2147483647] "mm" Vector__XXX
 SG_ AppRateDistance_Min m19 : 32|32@1- (1,0) [0|2147483647] "mm" Vector__XXX
 SG_ AppRateDistance_Max m20 : 32|32@1- (1,0) [0|2147483647] "mm" Vector__XXX
 SG_ AppRateVolumePerVolume_Set m21 : 32|32@1- (1,0) [0|2147483647] "mm³/m³" Vector__XXX
 SG_ AppRateVolumePerVolume_Act m22 : 32|32@1- (1,0) [0|2147483647] "mm³/m³" Vector__XXX
 SG_ AppRateVolumePerVolume_Def m23 : 32|32@1- (1,0) [0|2147483647] "mm³/m³" Vector__XXX
 SG_ AppRateVolumePerVolume_Min m24 : 32|32@1- (1,0) [0|2147483647] "mm³/m³" Vector__XXX
 SG_ AppRateVolumePerVolume_Max m25 : 32|32@1- (1,0) [0|2147483647] "mm³/m³" Vector__XXX
 SG_ AppRateMassPerMass_Set m26 : 32|32@1- (1,0) [0|2147483647] "mg/kg" Vector__XXX
 SG_ AppRateMassPerMass_Act m27 : 32|32@1- (1,0) [0|2147483647] "mg/kg" Vector__XXX
 SG_ AppRateMassPerMass_Def m28 : 32|32@1- (1,0) [0|2147483647] "mg/kg" Vector__XXX
 SG_ AppRateMassPerMass_Min m29 : 32|32@1- (1,0) [0|2147483647] "mg/kg" Vector__XXX
 SG_ AppRateMassPerMass_Max m30 : 32|32@1- (1,0) [0|2147483647] "mg/kg" Vector__XXX
 SG_ AppRateVolumePerMass_Set m31 : 32|32@1- (1,0) [0|2147483647] "mm³/kg" Vector__XXX
 SG_ AppRateVolumePerMass_Act m32 : 32|32@1- (1,0) [0|2147483647] "mm³/kg" Vector__XXX
 SG_ AppRateVolumePerMass_Def m33 : 32|32@1- (1,0) [0|2147483647] "mm³/kg" Vector__XXX
 SG_ AppRateVolumePerMass_Min m34 : 32|32@1- (1,0) [0|2147483647] "mm³/kg" Vector__XXX
 SG_ AppRateVolumePerMass_Max m35 : 32|32@1- (1,0) [0|2147483647] "mm³/kg" Vector__XXX
 SG_ AppRateVolumePerTime_Set m36 : 32|32@1- (1,0) [0|2147483647] "mm³/s" Vector__XXX
 SG_ AppRateVolumePerTime_Act m37 : 32|32@1- (1,0) [0|2147483647] "mm³/s" Vector__XXX
 SG_ AppRateVolumePerTime_Def m38 : 32|32@1- (1,0) [0|2147483647] "mm³/s" Vector__XXX
 SG_ AppRateVolumePerTime_Min m39 : 32|32@1- (1,0) [0|2147483647] "mm³/s" Vector__XXX
 SG_ AppRateVolumePerTime_Max m40 : 32|32@1- (1,0) [0|2147483647] "mm³/s" Vector__XXX
 SG_ AppRateMassPerTime_Set m41 : 32|32@1- (1,0) [0|2147483647] "mg/s" Vector__XXX
 SG_ AppRateMassPerTime_Act m42 : 32|32@1- (1,0) [0|2147483647] "mg/s" Vector__XXX
 SG_ AppRateMassPerTime_Def m43 : 32|32@1- (1,0) [0|2147483647] "mg/s" Vector__XXX
 SG_ AppRateMassPerTime_Min m44 : 32|32@1- (1,0) [0|2147483647] "mg/s" Vector__XXX
 SG_ AppRateMassPerTime_Max m45 : 32|32@1- (1,0) [0|2147483647] "mg/s" Vector__XXX
 SG_ AppRateCountPerTime_Set m46 : 32|32@1- (0.001,0) [0|2147483.647] "1/s" Vector__XXX
 SG_ AppRateCountPerTime_Act m47 : 32|32@1- (0.001,0) [0|2147483.647] "1/s" Vector__XXX
 SG_ AppRateCountPerTime_Def m48 : 32|32@1- (0.001,0) [0|2147483.647] "1/s" Vector__XXX
 SG_ AppRateCountPerTime_Min m49 : 32|32@1- (0.001,0) [0|2147483.647] "1/s" Vector__XXX
 SG_ AppRateCountPerTime_Max m50 : 32|32@1- (0.001,0) [0|2147483.647] "1/s" Vector__XXX
 SG_ SetTillageDepth_Set m51 : 32|32@1- (1,0) [0|2147483647] "mm" Vector__XXX
 SG_ TillageDepth_Act m52 : 32|32@1- (1,0) [0|2147483647] "mm" Vector__XXX
 SG_ TillageDepth_Def m53 : 32|32@1- (1,0) [0|2147483647] "mm" Vector__XXX
 SG_ TillageDepth_Min m54 : 32|32@1- (1,0) [0|2147483647] "mm" Vector__XXX
 SG_ TillageDepth_Max m55 : 32|32@1- (1,0) [0|2147483647] "mm" Vector__XXX
 SG_ SeedingDeph_Set m56 : 32|32@1- (1,0) [0|2147483647] "mm" Vector__XXX
 SG_ SeedingDeph_Act m57 : 32|32@1- (1,0) [0|2147483647] "mm" Vector__XXX
 SG_ SeedingDeph_Def m58 : 32|32@1- (1,0) [0|2147483647] "mm" Vector__XXX
 SG_ SeedingDeph_Min m59 : 32|32@1- (1,0) [0|2147483647] "mm" Vector__XXX
 SG_ SeedingDeph_Max m60 : 32|32@1- (1,0) [0|2147483647] "mm" Vector__XXX
 SG_ WorkingHeight_Set m61 : 32|32@1- (1,0) [0|2147483647] "mm" Vector__XXX
 SG_ WorkingHeight_Act m62 : 32|32@1- (1,0) [0|2147483647] "mm" Vector__XXX
 SG_ WorkingHeight_Def m63 : 32|32@1- (1,0) [0|2147483647] "mm" Vector__XXX
 SG_ WorkingHeight_Min m64 : 32|32@1- (1,0) [0|2147483647] "mm" Vector__XXX
 SG_ WorkingHeight_Max m65 : 32|32@1- (1,0) [0|2147483647] "mm" Vector__XXX
 SG_ WorkingWidth_Set m66 : 32|32@1- (1,0) [0|2147483647] "mm" Vector__XXX
 SG_ WorkingWidth_Act m67 : 32|32@1- (1,0) [0|2147483647] "mm" Vector__XXX
 SG_ WorkingWidth_Def m68 : 32|32@1- (1,0) [0|2147483647] "mm" Vector__XXX
 SG_ WorkingWidth_Min m69 : 32|32@1- (1,0) [0|2147483647] "mm" Vector__XXX
 SG_ WorkingWidth_Max m70 : 32|32@1- (1,0) [0|2147483647] "mm" Vector__XXX
 SG_ ContentAsVolume_Set m71 : 32|32@1- (1,0) [0|2147483647] "ml" Vector__XXX
 SG_ ContentAsVolume_Act m72 : 32|32@1- (1,0) [0|2147483647] "ml" Vector__XXX
 SG_ ContentAsVolume_Max m73 : 32|32@1- (1,0) [0|2147483647] "ml" Vector__XXX
 SG_ ContentAsMass_Set m74 : 32|32@1- (1,0) [0|2147483647] "g" Vector__XXX
 SG_ ContentAsMass_Act m75 : 32|32@1- (1,0) [0|2147483647] "g" Vector__XXX
 SG_ ContentAsMass_Max m76 : 32|32@1- (1,0) [0|2147483647] "g" Vector__XXX
 SG_ ContentAsCount_Set m77 : 32|32@1- (1,0) [0|2147483647] "" Vector__XXX
 SG_ ContentAsCount_Act m78 : 32|32@1- (1,0) [0|2147483647] "" Vector__XXX
 SG_ ContentAsCount_Max m79 : 32|32@1- (1,0) [0|2147483647] "" Vector__XXX
 SG_ AccumulatedAppAsVolume m80 : 32|32@1- (1,0) [0|2147483647] "l" Vector__XXX
 SG_ AccumulatedAppAsMass m81 : 32|32@1- (1,0) [0|2147483647] "kg" Vector__XXX
 SG_ AccumulatedAppAsCount m82 : 32|32@1- (1,0) [0|2147483647] "" Vector__XXX
 SG_ YieldVolumePerArea m83 : 32|32@1- (1,0) [0|2147483647] "ml/m²" Vector__XXX
 SG_ YieldMassPerArea m84 : 32|32@1- (1,0) [0|2147483647] "mg/m²" Vector__XXX
 SG_ YieldCountPerArea m85 : 32|32@1- (0.001,0) [0|2147483.647] "1/m²" Vector__XXX
 SG_ YieldVolumePerTime m86 : 32|32@1- (1,0) [0|2147483647] "ml/s" Vector__XXX
 SG_ YieldMassPerTime m87 : 32|32@1- (1,0) [0|2147483647] "mg/s" Vector__XXX
 SG_ YieldCountPerTime m88 : 32|32@1- (0.001,0) [0|2147483.647] "1/s" Vector__XXX
 SG_ AccumulatedYieldAsVolume m89 : 32|32@1- (1,0) [0|2147483647] "ml" Vector__XXX
 SG_ AccumulatedYieldAsMass m90 : 32|32@1- (1,0) [0|2147483647] "g" Vector__XXX
 SG_ AccumulatedYieldAsCount m91 : 32|32@1- (1,0) [0|2147483647] "" Vector__XXX
 SG_ CropYieldLossVolumePerArea m92 : 32|32@1- (1,0) [0|2147483647] "ml/m²" Vector__XXX
 SG_ CropYieldLossMassPerArea m93 : 32|32@1- (1,0) [0|2147483647] "mg/m²" Vector__XXX
 SG_ CropYieldLossCountPerArea m94 : 32|32@1- (0.001,0) [0|2147483.647] "1/m²" Vector__XXX
 SG_ CropYieldLossVolumePerTime m95 : 32|32@1- (1,0) [0|2147483647] "ml/s" Vector__XXX
 SG_ CropYieldLossMassPerTime m96 : 32|32@1- (1,0) [0|2147483647] "mg/s" Vector__XXX
 SG_ CropYieldLossCountPerTime m97 : 32|32@1- (0.001,0) [0|2147483.647] "1/s" Vector__XXX
 SG_ CropYieldLoss m98 : 32|32@1- (1,0) [0|2147483647] "ppm" Vector__XXX
 SG_ MoistureInCropYield m99 : 32|32@1- (1,0) [0|2147483647] "ppm" Vector__XXX
 SG_ DirtMaterialInCropYield m100 : 32|32@1- (1,0) [0|2147483647] "ppm" Vector__XXX
 SG_ BaleWidth_Set m101 : 32|32@1- (1,0) [0|2147483647] "mm" Vector__XXX
 SG_ BaleWidth_Act m102 : 32|32@1- (1,0) [0|2147483647] "mm" Vector__XXX
 SG_ BaleWidth_Def m103 : 32|32@1- (1,0) [0|2147483647] "mm" Vector__XXX
 SG_ BaleWidth_Min m104 : 32|32@1- (1,0) [0|2147483647] "mm" Vector__XXX
 SG_ BaleWidth_Max m105 : 32|32@1- (1,0) [0|2147483647] "mm" Vector__XXX
 SG_ BaleHeight_Set m106 : 32|32@1- (1,0) [0|2147483647] "mm" Vector__XXX
 SG_ BaleHeight_Act m107 : 32|32@1- (1,0) [0|2147483647] "mm" Vector__XXX
 SG_ BaleHeight_Def m108 : 32|32@1- (1,0) [0|2147483647] "mm" Vector__XXX
 SG_ BaleHeight_Min m109 : 32|32@1- (1,0) [0|2147483647] "mm" Vector__XXX
 SG_ BaleHeight_Max m110 : 32|32@1- (1,0) [0|2147483647] "mm" Vector__XXX
 SG_ BaleSize_Set m111 : 32|32@1- (1,0) [0|2147483647] "mm" Vector__XXX
 SG_ BaleSize_Act m112 : 32|32@1- (1,0) [0|2147483647] "mm" Vector__XXX
 SG_ BaleSize_Def m113 : 32|32@1- (1,0) [0|2147483647] "mm" Vector__XXX
 SG_ BaleSize_Min m114 : 32|32@1- (1,0) [0|2147483647] "mm" Vector__XXX
 SG_ BaleSize_Max m115 : 32|32@1- (1,0) [0|2147483647] "mm" Vector__XXX
 SG_ AccumulatedArea m116 : 32|32@1- (1,0) [0|2147483647] "m²" Vector__XXX
 SG_ AccumulatedDistanceInWork m117 : 32|32@1- (1,0) [0|2147483647] "mm" Vector__XXX
 SG_ AccumulatedDistanceOutWork m118 : 32|32@1- (1,0) [0|2147483647] "mm" Vector__XXX
 SG_ AccumulatedTimeInWork m119 : 32|32@1- (1,0) [0|2147483647] "s" Vector__XXX
 SG_ AccumulatedTimeOutWork m120 : 32|32@1- (1,0) [0|2147483647] "s" Vector__XXX
 SG_ PrdoucDensityMassPerArea m121 : 32|32@1- (1,0) [0|2147483647] "g/l" Vector__XXX
 SG_ PrdoucDensityMassPerCount m122 : 32|32@1- (1,0) [0|2147483647] "mg/1000" Vector__XXX
 SG_ PrdoucDensityVolumePerCount m123 : 32|32@1- (1,0) [0|2147483647] "ml/1000" Vector__XXX

CM_ BO_ 2365458942 "Tractor Facilities response message";
CM_ SG_ 2365458942 LimitStatusReporting "Parameter used to respond to a request of a facility of a tractor ECU";
CM_ BO_ 2566842110 "Time/Date";
CM_ BO_ 2566787070 "Language Command";
CM_ BO_ 2566843646 "Vehicle Identification";
CM_ BO_ 2362179200 "Request for Repetition Rates";
CM_ SG_ 2362179200 ErrorElementNumber "Device Element Number";
CM_ SG_ 2362179200 ErrorDDI "Data Dictionary Identifier";
CM_ SG_ 2362179200 Command "Process Data Command";
CM_ SG_ 2362179200 ElementNumber "Device Element Number";
CM_ SG_ 2362179200 DDI "Data Dictionary Identifier";
CM_ SG_ 2362179200 MinMassPerAreaAppRate "Minimum Application Rate specified as mass per area";
CM_ SG_ 2362179200 DataDictionaryVersion "This DDE is used to specify which version of the Data Dictionary is being used.";
CM_ SG_ 2362179200 RequestDefaultProcessData "Request Default Process Data.";
CM_ SG_ 2362179200 AreaPerTimeCapacity "Area per time capacity";
CM_ SG_ 2362179200 FuelConsumptionPerArea "Fuel consumption per area";
CM_ SG_ 2362179200 FuelConsumptionPerTime "Fuel consumption per time";
CM_ SG_ 2362179200 TotalFuelConsumption "Accumulated Fuel Consumption as Counter";
CM_ SG_ 2362179200 LogCount "Log Counter, may be used to control data log record generation on a
Task Controller";
CM_ SG_ 2362179200 PitchAngle "Pitch Angle of a DeviceElement";
CM_ SG_ 2362179200 RollAngle "Roll Angle of a DeviceElement";
CM_ SG_ 2362179200 YawAngle "Pivot / Yaw Angle of a DeviceElement";
CM_ SG_ 2362179200 ActualValueTimeLatency "Temporal Latency valid for the actual value of a Device Element";
CM_ SG_ 2362179200 SetpointTimeLatency "Temporal Latency valid for the setpoint values of a Device Element";
CM_ SG_ 2362179200 PercentageAppRateSetpoint "Application Rate expressed as percentage";
CM_ SG_ 2362179200 DeviceCountCapacity "DeviceElement Count Capacity, dimension of a DeviceElement";
CM_ SG_ 2362179200 DeviceMassCapacity "DeviceElement Mass Capacity, dimension of a DeviceElement.";
CM_ SG_ 2362179200 DeviceVolumeCapacity "DeviceElement Volume Capacity, dimension of a DeviceElement.";
CM_ SG_ 2362179200 DeviceElementOffsetZ "Z direction offset of a DeviceElement relative to  Device.";
CM_ SG_ 2362179200 DeviceElementOffsetY "Y direction offset of a DeviceElement relative to  Device.";
CM_ SG_ 2362179200 DeviceElementOffsetX "X direction offset of a DeviceElement relative to a Device.";
CM_ SG_ 2362179200 AuxiliaryValveInvertPorts "Command valve to swap extend and retract ports, easier than redoing
plumbing on valve.";
CM_ SG_ 2362179200 AuxiliaryValveProgressivRetract "Define non-linear releationship between command and flow by 2nd
degree polynomium.";
CM_ SG_ 2362179200 AuxiliaryValveProgressivExtend "Define non-linear releationship between command and flow by 2nd
degree polynomium.";
CM_ SG_ 2362179200 AuxiliaryValveFloatThreshold "Safety function. Current output of valve must be above threshold before
float command is allowed.";
CM_ SG_ 2362179200 AuxiliaryValveRampRetractDown "The valve will apply a ramp to the Auxiliary ValveCommand
PortFlowCommand, to limit the acceleration or deceleration of flow.";
CM_ SG_ 2362179200 AuxiliaryValveRampRetractUp "The valve will apply a ramp to theAuxiliary ValveCommand
PortFlowCommand, to limit the acceleration or deceleration of flow.";
CM_ SG_ 2362179200 AuxiliaryValveRampExtendDown "The valve will apply a ramp to the Auxiliary ValveCommand
PortFlowCommand, to limit the acceleration or deceleration of flow.";
CM_ SG_ 2362179200 AuxiliaryValveScalingRetract "Factor to apply to AuxValveCommand PortFlowCommand.";
CM_ SG_ 2362179200 AuxiliaryValveScalingExtend "Factor to apply to AuxValveCommand PortFlowCommand.";
CM_ SG_ 2362179200 AuxiliaryRampExtendUp "The valve will apply a ramp to the Auxiliary ValveCommand
PortFlowCommand, to limit the acceleration or deceleration of flow.";
CM_ SG_ 2362179200 AppRateVolumePerArea_Set "Setpoint Application Rate specified as volume per area";
CM_ SG_ 2362179200 AppRateVolumePerArea_Act "Actual Application Rate specified as volume per area";
CM_ SG_ 2362179200 AppRateVolumePerArea_Def "Default Application Rate specified as volume per area";
CM_ SG_ 2362179200 AppRateVolumePerArea_Min "Minimum Application Rate specified as volume per area";
CM_ SG_ 2362179200 AppRateVolumePerArea_Max "Maximum Application Rate specified as volume per area";
CM_ SG_ 2362179200 AppRateMassPerArea_Set "Setpoint Application Rate specified as mass per area";
CM_ SG_ 2362179200 AppRateMassPerArea_Act "Actual Application Rate specified as mass per area";
CM_ SG_ 2362179200 AppRateMassPerArea_Def "Default Application Rate specified as mass per area";
CM_ SG_ 2362179200 AppRateMassPerArea_Min "Minimum Application Rate specified as mass per area";
CM_ SG_ 2362179200 AppRateMassPerArea_Max "Maximum Application Rate specified as mass per area";
CM_ SG_ 2362179200 AppRateCountPerArea_Set "Setpoint Application Rate specified as count per area";
CM_ SG_ 2362179200 AppRateCountPerArea_Act "Actual Application Rate specified as count per area";
CM_ SG_ 2362179200 AppRateCountPerArea_Def "Default Application Rate specified as count per area";
CM_ SG_ 2362179200 AppRateCountPerArea_Min "Minimum Application Rate specified as count per area";
CM_ SG_ 2362179200 AppRateCountPerArea_Max "Maximum Application Rate specified as count per area";
CM_ SG_ 2362179200 SetAppRateDistance_Set "Setpoint Application Rate specified as distance";
CM_ SG_ 2362179200 AppRateDistance_Act "Actual Application Rate specified as distance";
CM_ SG_ 2362179200 AppRateDistance_Def "Default Application Rate specified as distance";
CM_ SG_ 2362179200 AppRateDistance_Min "Minimum Application Rate specified as distance";
CM_ SG_ 2362179200 AppRateDistance_Max "Maximum Application Rate specified as distance";
CM_ SG_ 2362179200 AppRateVolumePerVolume_Set "Setpoint Application Rate specified as volume per volume";
CM_ SG_ 2362179200 AppRateVolumePerVolume_Act "Actual Application Rate specified as volume per volume";
CM_ SG_ 2362179200 AppRateVolumePerVolume_Def "Default Application Rate specified as volume per volume";
CM_ SG_ 2362179200 AppRateVolumePerVolume_Min "Minimum Application Rate specified as volume per volume";
CM_ SG_ 2362179200 AppRateVolumePerVolume_Max "Maximum Application Rate specified as volume per volume";
CM_ SG_ 2362179200 AppRateMassPerMass_Set "Setpoint Application Rate specified as mass per mass";
CM_ SG_ 2362179200 AppRateMassPerMass_Act "Actual Application Rate specified as mass per mass";
CM_ SG_ 2362179200 AppRateMassPerMass_Def "Default Application Rate specified as mass per mass";
CM_ SG_ 2362179200 AppRateMassPerMass_Min "Minimum Application Rate specified as mass per mass";
CM_ SG_ 2362179200 AppRateMassPerMass_Max "Maximum Application Rate specified as mass per mass";
CM_ SG_ 2362179200 AppRateVolumePerMass_Set "Setpoint Application Rate specified as volume per mass";
CM_ SG_ 2362179200 AppRateVolumePerMass_Act "Actual Application Rate specified as volume per mass";
CM_ SG_ 2362179200 AppRateVolumePerMass_Def "Default Application Rate specified as volume per mass";
CM_ SG_ 2362179200 AppRateVolumePerMass_Min "Minimum Application Rate specified as volume per mass";
CM_ SG_ 2362179200 AppRateVolumePerMass_Max "Maximum Application Rate specified as volume per mass";
CM_ SG_ 2362179200 AppRateVolumePerTime_Set "Setpoint Application Rate specified as volume per time";
CM_ SG_ 2362179200 AppRateVolumePerTime_Act "Actual Application Rate specified as volume per time";
CM_ SG_ 2362179200 AppRateVolumePerTime_Def "Default Application Rate specified as volume per time";
CM_ SG_ 2362179200 AppRateVolumePerTime_Min "Minimum Application Rate specified as volume per time";
CM_ SG_ 2362179200 AppRateVolumePerTime_Max "Maximum Application Rate specified as volume per time";
CM_ SG_ 2362179200 AppRateMassPerTime_Set "Setpoint Application Rate specified as mass per time";
CM_ SG_ 2362179200 AppRateMassPerTime_Act "Actual Application Rate specified as mass per time";
CM_ SG_ 2362179200 AppRateMassPerTime_Def "Defaut Application Rate specified as mass per time";
CM_ SG_ 2362179200 AppRateMassPerTime_Min "Minimum Application Rate specified as mass per time";
CM_ SG_ 2362179200 AppRateMassPerTime_Max "Maximum Application Rate specified as mass per time";
CM_ SG_ 2362179200 AppRateCountPerTime_Set "Setpoint Application Rate specified as count per time";
CM_ SG_ 2362179200 AppRateCountPerTime_Act "Actual Application Rate specified as count per time";
CM_ SG_ 2362179200 AppRateCountPerTime_Def "Default Application Rate specified as count per time";
CM_ SG_ 2362179200 AppRateCountPerTime_Min "Minimum Application Rate specified as count per time";
CM_ SG_ 2362179200 AppRateCountPerTime_Max "Maximum Application Rate specified as count per time";
CM_ SG_ 2362179200 SetTillageDepth_Set "Setpoint Tillage Depth of Machine Element below soil surface, value increases with depth";
CM_ SG_ 2362179200 TillageDepth_Act "Actual Tillage Depth of Machine Element below soil surface, value increases with depth";
CM_ SG_ 2362179200 TillageDepth_Def "Default Tillage Depth of Machine Element below soil surface, value increases with depth";
CM_ SG_ 2362179200 TillageDepth_Min "Minimum Tillage Depth of Machine Element below soil surface, value increases with depth";
CM_ SG_ 2362179200 TillageDepth_Max "Maximum Tillage Depth of Machine Element below soil surface, value increases with depth";
CM_ SG_ 2362179200 SeedingDeph_Set "Setpoint Seeding Depth of Machine Element below soil surface, value increases with depth";
CM_ SG_ 2362179200 SeedingDeph_Act "Setpoint Seeding Depth of Machine Element below soil surface, value increases with depth";
CM_ SG_ 2362179200 SeedingDeph_Def "Setpoint Seeding Depth of Machine Element below soil surface, value increases with depth";
CM_ SG_ 2362179200 SeedingDeph_Min "Setpoint Seeding Depth of Machine Element below soil surface, value increases with depth";
CM_ SG_ 2362179200 SeedingDeph_Max "Setpoint Seeding Depth of Machine Element below soil surface, value increases with depth";
CM_ SG_ 2362179200 WorkingHeight_Set "Setpoint Working Height of Machine Element above crop or soil";
CM_ SG_ 2362179200 WorkingHeight_Act "Actual Working Height of Machine Element above crop or soil";
CM_ SG_ 2362179200 WorkingHeight_Def "Default Working Height of Machine Element above crop or soil";
CM_ SG_ 2362179200 WorkingHeight_Min "Minimum Working Height of Machine Element above crop or soil";
CM_ SG_ 2362179200 WorkingHeight_Max "Maximum Working Height of Machine Element above crop or soil";
CM_ SG_ 2362179200 WorkingWidth_Set "Setpoint Working Width of Machine Element";
CM_ SG_ 2362179200 WorkingWidth_Act "Actual Working Width of Machine Element";
CM_ SG_ 2362179200 WorkingWidth_Def "Default Working Width of Machine Element";
CM_ SG_ 2362179200 WorkingWidth_Min "Minimum Working Width of Machine Element";
CM_ SG_ 2362179200 WorkingWidth_Max "Maximum Working Width of Machine Element";
CM_ SG_ 2362179200 ContentAsVolume_Set "Setpoint Machine Element Content specified as volume";
CM_ SG_ 2362179200 ContentAsVolume_Act "Actual Machine Element Content specified as volume";
CM_ SG_ 2362179200 ContentAsVolume_Max "Maximum Machine Element Content specified as volume";
CM_ SG_ 2362179200 ContentAsMass_Set "Setpoint Machine Element Content specified as mass";
CM_ SG_ 2362179200 ContentAsMass_Act "Actual Machine Element Content specified as mass";
CM_ SG_ 2362179200 ContentAsMass_Max "Maximum Machine Element Content specified as mass";
CM_ SG_ 2362179200 ContentAsCount_Set "Setpoint Machine Element Content specified as count";
CM_ SG_ 2362179200 ContentAsCount_Act "Actual Machine Element Content specified as count";
CM_ SG_ 2362179200 ContentAsCount_Max "Maximum Machine Element Content specified as count";
CM_ SG_ 2362179200 AccumulatedAppAsVolume "Accumulated Application specified as volume";
CM_ SG_ 2362179200 AccumulatedAppAsMass "Accumulated Application specified as mass";
CM_ SG_ 2362179200 AccumulatedAppAsCount "Accumulated Application specified as count";
CM_ SG_ 2362179200 YieldVolumePerArea "Yield as volume per area";
CM_ SG_ 2362179200 YieldMassPerArea "Yield as mass per area";
CM_ SG_ 2362179200 YieldCountPerArea "Yield as count per area";
CM_ SG_ 2362179200 YieldVolumePerTime "Yield as volume per area";
CM_ SG_ 2362179200 YieldMassPerTime "Yield as mass per area";
CM_ SG_ 2362179200 YieldCountPerTime "Yield as count per area";
CM_ SG_ 2362179200 AccumulatedYieldAsVolume "Accumulated Yield specified as volume";
CM_ SG_ 2362179200 AccumulatedYieldAsMass "Accumulated Yield specified as mass";
CM_ SG_ 2362179200 AccumulatedYieldAsCount "Accumulated Yield specified as count";
CM_ SG_ 2362179200 CropYieldLossVolumePerArea "Crop yield loss as volume per area";
CM_ SG_ 2362179200 CropYieldLossMassPerArea "Crop yield loss as mass per area";
CM_ SG_ 2362179200 CropYieldLossCountPerArea "Crop yield loss as count per area";
CM_ SG_ 2362179200 CropYieldLossVolumePerTime "Crop yield loss as volume per time";
CM_ SG_ 2362179200 CropYieldLossMassPerTime "Crop yield loss as mass per time";
CM_ SG_ 2362179200 CropYieldLossCountPerTime "Crop yield loss as count per time";
CM_ SG_ 2362179200 CropYieldLoss "Crop yield loss";
CM_ SG_ 2362179200 MoistureInCropYield "Moisture in crop yield";
CM_ SG_ 2362179200 DirtMaterialInCropYield "Dirt or foreign material in crop yield";
CM_ SG_ 2362179200 BaleWidth_Set "Setpoint Bale Width for square baler or round baler";
CM_ SG_ 2362179200 BaleWidth_Act "Actual Bale Width for square baler or round baler";
CM_ SG_ 2362179200 BaleWidth_Def "Default Bale Width for square baler or round baler";
CM_ SG_ 2362179200 BaleWidth_Min "Minimum Bale Width for square baler or round baler";
CM_ SG_ 2362179200 BaleWidth_Max "Maximum Bale Width for square baler or round baler";
CM_ SG_ 2362179200 BaleHeight_Set "Setpoint Bale Height is only applicable to square baler";
CM_ SG_ 2362179200 BaleHeight_Act "Actual Bale Height is only applicable to square baler";
CM_ SG_ 2362179200 BaleHeight_Def "Default Bale Height is only applicable to square baler";
CM_ SG_ 2362179200 BaleHeight_Min "Minimum Bale Height is only applicable to square baler";
CM_ SG_ 2362179200 BaleHeight_Max "Maximum Bale Height is only applicable to square baler";
CM_ SG_ 2362179200 BaleSize_Set "Setpoint Bale Size as length for a square baler or diameter for a round baler";
CM_ SG_ 2362179200 BaleSize_Act "Actual Bale Size as length for a square baler or diameter for a round baler";
CM_ SG_ 2362179200 BaleSize_Def "Default Bale Size as length for a square baler or diameter for a round baler";
CM_ SG_ 2362179200 BaleSize_Min "Minimum Bale Size as length for a square baler or diameter for a round baler";
CM_ SG_ 2362179200 BaleSize_Max "Maximum Bale Size as length for a square baler or diameter for a round baler";
CM_ SG_ 2362179200 AccumulatedArea "Accumulated Area";
CM_ SG_ 2362179200 AccumulatedDistanceInWork "Accumulated Distance in working position";
CM_ SG_ 2362179200 AccumulatedDistanceOutWork "Accumulated Distance out of working position";
CM_ SG_ 2362179200 AccumulatedTimeInWork "Accumulated Time in working position";
CM_ SG_ 2362179200 AccumulatedTimeOutWork "Accumulated Time out of working position";
CM_ SG_ 2362179200 PrdoucDensityMassPerArea "Product Density as mass per volume";
CM_ SG_ 2362179200 PrdoucDensityMassPerCount "Product Density as mass per count";
CM_ SG_ 2362179200 PrdoucDensityVolumePerCount "Product Density as volume per count";
CM_ BO_ 2362179319 "Request for Repetition Rates";
CM_ SG_ 2362179319 ErrorElementNumber "Device Element Number";
CM_ SG_ 2362179319 ErrorDDI "Data Dictionary Identifier";
CM_ SG_ 2362179319 Command "Process Data Command";
CM_ SG_ 2362179319 ElementNumber "Device Element Number";
CM_ SG_ 2362179319 DDI "Data Dictionary Identifier";
CM_ SG_ 2362179319 MinMassPerAreaAppRate "Minimum Application Rate specified as mass per area";
CM_ SG_ 2362179319 DataDictionaryVersion "This DDE is used to specify which version of the Data Dictionary is being used.";
CM_ SG_ 2362179319 RequestDefaultProcessData "Request Default Process Data.";
CM_ SG_ 2362179319 AreaPerTimeCapacity "Area per time capacity";
CM_ SG_ 2362179319 FuelConsumptionPerArea "Fuel consumption per area";
CM_ SG_ 2362179319 FuelConsumptionPerTime "Fuel consumption per time";
CM_ SG_ 2362179319 TotalFuelConsumption "Accumulated Fuel Consumption as Counter";
CM_ SG_ 2362179319 LogCount "Log Counter, may be used to control data log record generation on a
Task Controller";
CM_ SG_ 2362179319 PitchAngle "Pitch Angle of a DeviceElement";
CM_ SG_ 2362179319 RollAngle "Roll Angle of a DeviceElement";
CM_ SG_ 2362179319 YawAngle "Pivot / Yaw Angle of a DeviceElement";
CM_ SG_ 2362179319 ActualValueTimeLatency "Temporal Latency valid for the actual value of a Device Element";
CM_ SG_ 2362179319 SetpointTimeLatency "Temporal Latency valid for the setpoint values of a Device Element";
CM_ SG_ 2362179319 PercentageAppRateSetpoint "Application Rate expressed as percentage";
CM_ SG_ 2362179319 DeviceCountCapacity "DeviceElement Count Capacity, dimension of a DeviceElement";
CM_ SG_ 2362179319 DeviceMassCapacity "DeviceElement Mass Capacity, dimension of a DeviceElement.";
CM_ SG_ 2362179319 DeviceVolumeCapacity "DeviceElement Volume Capacity, dimension of a DeviceElement.";
CM_ SG_ 2362179319 DeviceElementOffsetZ "Z direction offset of a DeviceElement relative to  Device.";
CM_ SG_ 2362179319 DeviceElementOffsetY "Y direction offset of a DeviceElement relative to  Device.";
CM_ SG_ 2362179319 DeviceElementOffsetX "X direction offset of a DeviceElement relative to a Device.";
CM_ SG_ 2362179319 AuxiliaryValveInvertPorts "Command valve to swap extend and retract ports, easier than redoing
plumbing on valve.";
CM_ SG_ 2362179319 AuxiliaryValveProgressivRetract "Define non-linear releationship between command and flow by 2nd
degree polynomium.";
CM_ SG_ 2362179319 AuxiliaryValveProgressivExtend "Define non-linear releationship between command and flow by 2nd
degree polynomium.";
CM_ SG_ 2362179319 AuxiliaryValveFloatThreshold "Safety function. Current output of valve must be above threshold before
float command is allowed.";
CM_ SG_ 2362179319 AuxiliaryValveRampRetractDown "The valve will apply a ramp to the Auxiliary ValveCommand
PortFlowCommand, to limit the acceleration or deceleration of flow.";
CM_ SG_ 2362179319 AuxiliaryValveRampRetractUp "The valve will apply a ramp to theAuxiliary ValveCommand
PortFlowCommand, to limit the acceleration or deceleration of flow.";
CM_ SG_ 2362179319 AuxiliaryValveRampExtendDown "The valve will apply a ramp to the Auxiliary ValveCommand
PortFlowCommand, to limit the acceleration or deceleration of flow.";
CM_ SG_ 2362179319 AuxiliaryValveScalingRetract "Factor to apply to AuxValveCommand PortFlowCommand.";
CM_ SG_ 2362179319 AuxiliaryValveScalingExtend "Factor to apply to AuxValveCommand PortFlowCommand.";
CM_ SG_ 2362179319 AuxiliaryRampExtendUp "The valve will apply a ramp to the Auxiliary ValveCommand
PortFlowCommand, to limit the acceleration or deceleration of flow.";
CM_ SG_ 2362179319 AppRateVolumePerArea_Set "Setpoint Application Rate specified as volume per area";
CM_ SG_ 2362179319 AppRateVolumePerArea_Act "Actual Application Rate specified as volume per area";
CM_ SG_ 2362179319 AppRateVolumePerArea_Def "Default Application Rate specified as volume per area";
CM_ SG_ 2362179319 AppRateVolumePerArea_Min "Minimum Application Rate specified as volume per area";
CM_ SG_ 2362179319 AppRateVolumePerArea_Max "Maximum Application Rate specified as volume per area";
CM_ SG_ 2362179319 AppRateMassPerArea_Set "Setpoint Application Rate specified as mass per area";
CM_ SG_ 2362179319 AppRateMassPerArea_Act "Actual Application Rate specified as mass per area";
CM_ SG_ 2362179319 AppRateMassPerArea_Def "Default Application Rate specified as mass per area";
CM_ SG_ 2362179319 AppRateMassPerArea_Min "Minimum Application Rate specified as mass per area";
CM_ SG_ 2362179319 AppRateMassPerArea_Max "Maximum Application Rate specified as mass per area";
CM_ SG_ 2362179319 AppRateCountPerArea_Set "Setpoint Application Rate specified as count per area";
CM_ SG_ 2362179319 AppRateCountPerArea_Act "Actual Application Rate specified as count per area";
CM_ SG_ 2362179319 AppRateCountPerArea_Def "Default Application Rate specified as count per area";
CM_ SG_ 2362179319 AppRateCountPerArea_Min "Minimum Application Rate specified as count per area";
CM_ SG_ 2362179319 AppRateCountPerArea_Max "Maximum Application Rate specified as count per area";
CM_ SG_ 2362179319 SetAppRateDistance_Set "Setpoint Application Rate specified as distance";
CM_ SG_ 2362179319 AppRateDistance_Act "Actual Application Rate specified as distance";
CM_ SG_ 2362179319 AppRateDistance_Def "Default Application Rate specified as distance";
CM_ SG_ 2362179319 AppRateDistance_Min "Minimum Application Rate specified as distance";
CM_ SG_ 2362179319 AppRateDistance_Max "Maximum Application Rate specified as distance";
CM_ SG_ 2362179319 AppRateVolumePerVolume_Set "Setpoint Application Rate specified as volume per volume";
CM_ SG_ 2362179319 AppRateVolumePerVolume_Act "Actual Application Rate specified as volume per volume";
CM_ SG_ 2362179319 AppRateVolumePerVolume_Def "Default Application Rate specified as volume per volume";
CM_ SG_ 2362179319 AppRateVolumePerVolume_Min "Minimum Application Rate specified as volume per volume";
CM_ SG_ 2362179319 AppRateVolumePerVolume_Max "Maximum Application Rate specified as volume per volume";
CM_ SG_ 2362179319 AppRateMassPerMass_Set "Setpoint Application Rate specified as mass per mass";
CM_ SG_ 2362179319 AppRateMassPerMass_Act "Actual Application Rate specified as mass per mass";
CM_ SG_ 2362179319 AppRateMassPerMass_Def "Default Application Rate specified as mass per mass";
CM_ SG_ 2362179319 AppRateMassPerMass_Min "Minimum Application Rate specified as mass per mass";
CM_ SG_ 2362179319 AppRateMassPerMass_Max "Maximum Application Rate specified as mass per mass";
CM_ SG_ 2362179319 AppRateVolumePerMass_Set "Setpoint Application Rate specified as volume per mass";
CM_ SG_ 2362179319 AppRateVolumePerMass_Act "Actual Application Rate specified as volume per mass";
CM_ SG_ 2362179319 AppRateVolumePerMass_Def "Default Application Rate specified as volume per mass";
CM_ SG_ 2362179319 AppRateVolumePerMass_Min "Minimum Application Rate specified as volume per mass";
CM_ SG_ 2362179319 AppRateVolumePerMass_Max "Maximum Application Rate specified as volume per mass";
CM_ SG_ 2362179319 AppRateVolumePerTime_Set "Setpoint Application Rate specified as volume per time";
CM_ SG_ 2362179319 AppRateVolumePerTime_Act "Actual Application Rate specified as volume per time";
CM_ SG_ 2362179319 AppRateVolumePerTime_Def "Default Application Rate specified as volume per time";
CM_ SG_ 2362179319 AppRateVolumePerTime_Min "Minimum Application Rate specified as volume per time";
CM_ SG_ 2362179319 AppRateVolumePerTime_Max "Maximum Application Rate specified as volume per time";
CM_ SG_ 2362179319 AppRateMassPerTime_Set "Setpoint Application Rate specified as mass per time";
CM_ SG_ 2362179319 AppRateMassPerTime_Act "Actual Application Rate specified as mass per time";
CM_ SG_ 2362179319 AppRateMassPerTime_Def "Defaut Application Rate specified as mass per time";
CM_ SG_ 2362179319 AppRateMassPerTime_Min "Minimum Application Rate specified as mass per time";
CM_ SG_ 2362179319 AppRateMassPerTime_Max "Maximum Application Rate specified as mass per time";
CM_ SG_ 2362179319 AppRateCountPerTime_Set "Setpoint Application Rate specified as count per time";
CM_ SG_ 2362179319 AppRateCountPerTime_Act "Actual Application Rate specified as count per time";
CM_ SG_ 2362179319 AppRateCountPerTime_Def "Default Application Rate specified as count per time";
CM_ SG_ 2362179319 AppRateCountPerTime_Min "Minimum Application Rate specified as count per time";
CM_ SG_ 2362179319 AppRateCountPerTime_Max "Maximum Application Rate specified as count per time";
CM_ SG_ 2362179319 SetTillageDepth_Set "Setpoint Tillage Depth of Machine Element below soil surface, value increases with depth";
CM_ SG_ 2362179319 TillageDepth_Act "Actual Tillage Depth of Machine Element below soil surface, value increases with depth";
CM_ SG_ 2362179319 TillageDepth_Def "Default Tillage Depth of Machine Element below soil surface, value increases with depth";
CM_ SG_ 2362179319 TillageDepth_Min "Minimum Tillage Depth of Machine Element below soil surface, value increases with depth";
CM_ SG_ 2362179319 TillageDepth_Max "Maximum Tillage Depth of Machine Element below soil surface, value increases with depth";
CM_ SG_ 2362179319 SeedingDeph_Set "Setpoint Seeding Depth of Machine Element below soil surface, value increases with depth";
CM_ SG_ 2362179319 SeedingDeph_Act "Setpoint Seeding Depth of Machine Element below soil surface, value increases with depth";
CM_ SG_ 2362179319 SeedingDeph_Def "Setpoint Seeding Depth of Machine Element below soil surface, value increases with depth";
CM_ SG_ 2362179319 SeedingDeph_Min "Setpoint Seeding Depth of Machine Element below soil surface, value increases with depth";
CM_ SG_ 2362179319 SeedingDeph_Max "Setpoint Seeding Depth of Machine Element below soil surface, value increases with depth";
CM_ SG_ 2362179319 WorkingHeight_Set "Setpoint Working Height of Machine Element above crop or soil";
CM_ SG_ 2362179319 WorkingHeight_Act "Actual Working Height of Machine Element above crop or soil";
CM_ SG_ 2362179319 WorkingHeight_Def "Default Working Height of Machine Element above crop or soil";
CM_ SG_ 2362179319 WorkingHeight_Min "Minimum Working Height of Machine Element above crop or soil";
CM_ SG_ 2362179319 WorkingHeight_Max "Maximum Working Height of Machine Element above crop or soil";
CM_ SG_ 2362179319 WorkingWidth_Set "Setpoint Working Width of Machine Element";
CM_ SG_ 2362179319 WorkingWidth_Act "Actual Working Width of Machine Element";
CM_ SG_ 2362179319 WorkingWidth_Def "Default Working Width of Machine Element";
CM_ SG_ 2362179319 WorkingWidth_Min "Minimum Working Width of Machine Element";
CM_ SG_ 2362179319 WorkingWidth_Max "Maximum Working Width of Machine Element";
CM_ SG_ 2362179319 ContentAsVolume_Set "Setpoint Machine Element Content specified as volume";
CM_ SG_ 2362179319 ContentAsVolume_Act "Actual Machine Element Content specified as volume";
CM_ SG_ 2362179319 ContentAsVolume_Max "Maximum Machine Element Content specified as volume";
CM_ SG_ 2362179319 ContentAsMass_Set "Setpoint Machine Element Content specified as mass";
CM_ SG_ 2362179319 ContentAsMass_Act "Actual Machine Element Content specified as mass";
CM_ SG_ 2362179319 ContentAsMass_Max "Maximum Machine Element Content specified as mass";
CM_ SG_ 2362179319 ContentAsCount_Set "Setpoint Machine Element Content specified as count";
CM_ SG_ 2362179319 ContentAsCount_Act "Actual Machine Element Content specified as count";
CM_ SG_ 2362179319 ContentAsCount_Max "Maximum Machine Element Content specified as count";
CM_ SG_ 2362179319 AccumulatedAppAsVolume "Accumulated Application specified as volume";
CM_ SG_ 2362179319 AccumulatedAppAsMass "Accumulated Application specified as mass";
CM_ SG_ 2362179319 AccumulatedAppAsCount "Accumulated Application specified as count";
CM_ SG_ 2362179319 YieldVolumePerArea "Yield as volume per area";
CM_ SG_ 2362179319 YieldMassPerArea "Yield as mass per area";
CM_ SG_ 2362179319 YieldCountPerArea "Yield as count per area";
CM_ SG_ 2362179319 YieldVolumePerTime "Yield as volume per area";
CM_ SG_ 2362179319 YieldMassPerTime "Yield as mass per area";
CM_ SG_ 2362179319 YieldCountPerTime "Yield as count per area";
CM_ SG_ 2362179319 AccumulatedYieldAsVolume "Accumulated Yield specified as volume";
CM_ SG_ 2362179319 AccumulatedYieldAsMass "Accumulated Yield specified as mass";
CM_ SG_ 2362179319 AccumulatedYieldAsCount "Accumulated Yield specified as count";
CM_ SG_ 2362179319 CropYieldLossVolumePerArea "Crop yield loss as volume per area";
CM_ SG_ 2362179319 CropYieldLossMassPerArea "Crop yield loss as mass per area";
CM_ SG_ 2362179319 CropYieldLossCountPerArea "Crop yield loss as count per area";
CM_ SG_ 2362179319 CropYieldLossVolumePerTime "Crop yield loss as volume per time";
CM_ SG_ 2362179319 CropYieldLossMassPerTime "Crop yield loss as mass per time";
CM_ SG_ 2362179319 CropYieldLossCountPerTime "Crop yield loss as count per time";
CM_ SG_ 2362179319 CropYieldLoss "Crop yield loss";
CM_ SG_ 2362179319 MoistureInCropYield "Moisture in crop yield";
CM_ SG_ 2362179319 DirtMaterialInCropYield "Dirt or foreign material in crop yield";
CM_ SG_ 2362179319 BaleWidth_Set "Setpoint Bale Width for square baler or round baler";
CM_ SG_ 2362179319 BaleWidth_Act "Actual Bale Width for square baler or round baler";
CM_ SG_ 2362179319 BaleWidth_Def "Default Bale Width for square baler or round baler";
CM_ SG_ 2362179319 BaleWidth_Min "Minimum Bale Width for square baler or round baler";
CM_ SG_ 2362179319 BaleWidth_Max "Maximum Bale Width for square baler or round baler";
CM_ SG_ 2362179319 BaleHeight_Set "Setpoint Bale Height is only applicable to square baler";
CM_ SG_ 2362179319 BaleHeight_Act "Actual Bale Height is only applicable to square baler";
CM_ SG_ 2362179319 BaleHeight_Def "Default Bale Height is only applicable to square baler";
CM_ SG_ 2362179319 BaleHeight_Min "Minimum Bale Height is only applicable to square baler";
CM_ SG_ 2362179319 BaleHeight_Max "Maximum Bale Height is only applicable to square baler";
CM_ SG_ 2362179319 BaleSize_Set "Setpoint Bale Size as length for a square baler or diameter for a round baler";
CM_ SG_ 2362179319 BaleSize_Act "Actual Bale Size as length for a square baler or diameter for a round baler";
CM_ SG_ 2362179319 BaleSize_Def "Default Bale Size as length for a square baler or diameter for a round baler";
CM_ SG_ 2362179319 BaleSize_Min "Minimum Bale Size as length for a square baler or diameter for a round baler";
CM_ SG_ 2362179319 BaleSize_Max "Maximum Bale Size as length for a square baler or diameter for a round baler";
CM_ SG_ 2362179319 AccumulatedArea "Accumulated Area";
CM_ SG_ 2362179319 AccumulatedDistanceInWork "Accumulated Distance in working position";
CM_ SG_ 2362179319 AccumulatedDistanceOutWork "Accumulated Distance out of working position";
CM_ SG_ 2362179319 AccumulatedTimeInWork "Accumulated Time in working position";
CM_ SG_ 2362179319 AccumulatedTimeOutWork "Accumulated Time out of working position";
CM_ SG_ 2362179319 PrdoucDensityMassPerArea "Product Density as mass per volume";
CM_ SG_ 2362179319 PrdoucDensityMassPerCount "Product Density as mass per count";
CM_ SG_ 2362179319 PrdoucDensityVolumePerCount "Product Density as volume per count";
BA_DEF_ SG_  "GenSigStartValue" INT -2147483648 2147483647;
BA_DEF_ SG_  "GenSigSendType" ENUM  "Cyclic","OnWrite","OnWriteWithRepetition","OnChange","OnChangeWithRepetition","IfActive","IfActiveWithRepetition","NoSigSendType";
BA_DEF_ SG_  "SigType" ENUM  "Default","Range","RangeSigned","ASCII","Discrete","Control","ReferencePGN","DTC","StringDelimiter","StringLength","StringLengthControl";
BA_DEF_ SG_  "SPN" INT 0 524287;
BA_DEF_ BO_  "GenMsgRequestable" INT 0 1;
BA_DEF_ BO_  "GenMsgCycleTime" INT 0 3600000;
BA_DEF_ BO_  "GenMsgSendType" ENUM  "cyclic","reserved","cyclicIfActive","reserved","reserved","reserved","reserved","reserved","noMsgSendType","vector_leerstring";
BA_DEF_ BO_  "VFrameFormat" ENUM  "StandardCAN","ExtendedCAN","reserved","J1939PG","vector_leerstring";
BA_DEF_ BO_  "SingleFrame" INT 0 1;
BA_DEF_ SG_  "DDI" INT 0 65535;
BA_DEF_ SG_  "SystemSignalLongSymbol" STRING ;
BA_DEF_DEF_  "GenSigStartValue" 0;
BA_DEF_DEF_  "GenSigSendType" "NoSigSendType";
BA_DEF_DEF_  "SigType" "Default";
BA_DEF_DEF_  "SPN" 0;
BA_DEF_DEF_  "GenMsgRequestable" 1;
BA_DEF_DEF_  "GenMsgCycleTime" 0;
BA_DEF_DEF_  "GenMsgSendType" "noMsgSendType";
BA_DEF_DEF_  "VFrameFormat" "J1939PG";
BA_DEF_DEF_  "SingleFrame" 1;
BA_DEF_DEF_  "DDI" 0;
BA_DEF_DEF_  "SystemSignalLongSymbol" "";
BA_ "GenMsgCycleTime" BO_ 2365458942 100;
BA_ "GenMsgCycleTime" BO_ 2566842110 100;
BA_ "GenMsgCycleTime" BO_ 2566787070 100;
BA_ "SigType" SG_ 2365458942 SpeedInfo_EngineSpeed 4;
BA_ "SigType" SG_ 2365458942 SpeedInfo_GroundBasedSpeed 4;
BA_ "SigType" SG_ 2365458942 SpeedInfo_WheelBasedSpeed 4;
BA_ "SigType" SG_ 2365458942 PowerMgt_MaintainPower 4;
BA_ "SigType" SG_ 2365458942 PowerMgt_MaxTimeTractorPower 4;
BA_ "SigType" SG_ 2365458942 PowerMgt_KeySwitch 4;
BA_ "SigType" SG_ 2365458942 TractorClass 4;
BA_ "SigType" SG_ 2365458942 LanguageCmdStorageInTractorECU 4;
BA_ "SigType" SG_ 2365458942 Lighting_MinimalSet 4;
BA_ "SigType" SG_ 2365458942 PTOInfo_RearShaftEngagement 4;
BA_ "SigType" SG_ 2365458942 PTOInfo_RearShaftSpeed 4;
BA_ "SigType" SG_ 2365458942 HitchInfo_RearInWork 4;
BA_ "SigType" SG_ 2365458942 HitchInfo_RearPosition 4;
BA_ "SigType" SG_ 2365458942 EstimatedOrMeasuredAuxValveState 4;
BA_ "SigType" SG_ 2365458942 Light_FullImplLightingMessageSet 4;
BA_ "SigType" SG_ 2365458942 AddHitchParameter_RearDraft 4;
BA_ "SigType" SG_ 2365458942 SpeedAndDist_WheelBasedDirection 4;
BA_ "SigType" SG_ 2365458942 SpeedAndDist_WheelBasedDistance 4;
BA_ "SigType" SG_ 2365458942 SpeedAndDist_GndBasedDirection 4;
BA_ "SigType" SG_ 2365458942 SpeedAndDist_GndBasedDistance 4;
BA_ "SigType" SG_ 2365458942 TimeDate 4;
BA_ "SigType" SG_ 2365458942 AuxiliaryValveCmd 4;
BA_ "SigType" SG_ 2365458942 PTOCmd_RearPTOEngagementCmd 4;
BA_ "SigType" SG_ 2365458942 PTOCmd_RearPTOSpeedCmd 4;
BA_ "SigType" SG_ 2365458942 HitchCmd_RearHitchPosition 4;
BA_ "SigType" SG_ 2365458942 NavigPseudorangeNoiseStatistic 4;
BA_ "SigType" SG_ 2365458942 NavigSystemPositionData 4;
BA_ "SigType" SG_ 2365458942 NavigSystemHighOutputPosition 4;
BA_ "SigType" SG_ 2365458942 PTOCmd_FrontPTOEngagementCmd 4;
BA_ "SigType" SG_ 2365458942 PTOCmd_FrontPTOSpeedCmd 4;
BA_ "SigType" SG_ 2365458942 HitchCmd_FrontHitchPosition 4;
BA_ "SigType" SG_ 2365458942 AddHitchParameter__FrontDraft 4;
BA_ "SigType" SG_ 2365458942 PTOInfo_FrontShaftEngagement 4;
BA_ "SigType" SG_ 2365458942 PTOInfo_FrontShaftSpeed 4;
BA_ "SigType" SG_ 2365458942 HitchInfo_FrontInWork 4;
BA_ "SigType" SG_ 2365458942 HitchInfo_FrontPosition 4;
BA_ "SigType" SG_ 2566842110 Seconds 1;
BA_ "SigType" SG_ 2566842110 Minutes 1;
BA_ "SigType" SG_ 2566842110 Hours 1;
BA_ "SigType" SG_ 2566842110 Month 1;
BA_ "GenSigStartValue" SG_ 2566842110 Day 1;
BA_ "SigType" SG_ 2566842110 Day 1;
BA_ "SigType" SG_ 2566842110 Year 1;
BA_ "SigType" SG_ 2566842110 LocalMinuteOffset 1;
BA_ "SigType" SG_ 2566842110 LocalHourOffset 1;
BA_ "SigType" SG_ 2566787070 LanguageCodeCmd 3;
BA_ "SPN" SG_ 2566787070 LanguageCodeCmd 2410;
BA_ "SigType" SG_ 2566787070 TimeFormatCmd 4;
BA_ "SPN" SG_ 2566787070 TimeFormatCmd 2413;
BA_ "SigType" SG_ 2566787070 DecimalSymbolCmd 4;
BA_ "SPN" SG_ 2566787070 DecimalSymbolCmd 2411;
BA_ "SigType" SG_ 2566787070 DateFormatCmd 1;
BA_ "SPN" SG_ 2566787070 DateFormatCmd 2412;
BA_ "SigType" SG_ 2566787070 MassUnitCmd 4;
BA_ "SPN" SG_ 2566787070 MassUnitCmd 2417;
BA_ "SigType" SG_ 2566787070 VolumeUnitCmd 4;
BA_ "SPN" SG_ 2566787070 VolumeUnitCmd 2416;
BA_ "SigType" SG_ 2566787070 AreaUnitCmd 4;
BA_ "SPN" SG_ 2566787070 AreaUnitCmd 2415;
BA_ "SigType" SG_ 2566787070 DistanceUnitCmd 4;
BA_ "SPN" SG_ 2566787070 DistanceUnitCmd 2414;
BA_ "SigType" SG_ 2566787070 UnitsSystem 4;
BA_ "SigType" SG_ 2566787070 ForceUnits 4;
BA_ "SigType" SG_ 2566787070 PressureUnits 4;
BA_ "SigType" SG_ 2566787070 TemperatureUnits 4;
BA_ "SPN" SG_ 2566843646 VehicleIdentificationNumber 237;
BA_ "SigType" SG_ 2566843646 VehicleIdentificationNumber 8;
BA_ "SigType" SG_ 2362179200 ObjectIdOfFaultyObject 1;
BA_ "SigType" SG_ 2362179200 ParentObjectIdOfFaultyObject 1;
BA_ "SigType" SG_ 2362179200 TemperatureUnits 4;
BA_ "SigType" SG_ 2362179200 PressureUnits 4;
BA_ "SigType" SG_ 2362179200 ForceUnits 4;
BA_ "SigType" SG_ 2362179200 UnitsSystem 4;
BA_ "SigType" SG_ 2362179200 DistanceUnitCmd 4;
BA_ "SPN" SG_ 2362179200 DistanceUnitCmd 2414;
BA_ "SigType" SG_ 2362179200 AreaUnitCmd 4;
BA_ "SPN" SG_ 2362179200 AreaUnitCmd 2415;
BA_ "SigType" SG_ 2362179200 VolumeUnitCmd 4;
BA_ "SPN" SG_ 2362179200 VolumeUnitCmd 2416;
BA_ "SigType" SG_ 2362179200 MassUnitCmd 4;
BA_ "SPN" SG_ 2362179200 MassUnitCmd 2417;
BA_ "SigType" SG_ 2362179200 DateFormatCmd 1;
BA_ "SPN" SG_ 2362179200 DateFormatCmd 2412;
BA_ "SigType" SG_ 2362179200 DecimalSymbolCmd 4;
BA_ "SPN" SG_ 2362179200 DecimalSymbolCmd 2411;
BA_ "SigType" SG_ 2362179200 TimeFormatCmd 4;
BA_ "SPN" SG_ 2362179200 TimeFormatCmd 2413;
BA_ "SigType" SG_ 2362179200 LanguageCodeCmd 3;
BA_ "SPN" SG_ 2362179200 LanguageCodeCmd 2410;
BA_ "DDI" SG_ 2362179200 MinMassPerAreaAppRate 152;
BA_ "DDI" SG_ 2362179200 RequestDefaultProcessData 57343;
BA_ "DDI" SG_ 2362179200 AreaPerTimeCapacity 151;
BA_ "DDI" SG_ 2362179200 FuelConsumptionPerArea 150;
BA_ "DDI" SG_ 2362179200 FuelConsumptionPerTime 149;
BA_ "DDI" SG_ 2362179200 TotalFuelConsumption 148;
BA_ "DDI" SG_ 2362179200 LogCount 147;
BA_ "DDI" SG_ 2362179200 PitchAngle 146;
BA_ "DDI" SG_ 2362179200 RollAngle 145;
BA_ "DDI" SG_ 2362179200 YawAngle 144;
BA_ "DDI" SG_ 2362179200 ActualValueTimeLatency 143;
BA_ "DDI" SG_ 2362179200 SetpointTimeLatency 142;
BA_ "DDI" SG_ 2362179200 WorkState 141;
BA_ "DDI" SG_ 2362179200 PercentageAppRateSetpoint 140;
BA_ "DDI" SG_ 2362179200 DeviceCountCapacity 139;
BA_ "DDI" SG_ 2362179200 DeviceMassCapacity 138;
BA_ "DDI" SG_ 2362179200 DeviceVolumeCapacity 137;
BA_ "DDI" SG_ 2362179200 DeviceElementOffsetZ 136;
BA_ "DDI" SG_ 2362179200 DeviceElementOffsetY 135;
BA_ "DDI" SG_ 2362179200 DeviceElementOffsetX 134;
BA_ "DDI" SG_ 2362179200 AuxiliaryValveInvertPorts 133;
BA_ "DDI" SG_ 2362179200 AuxiliaryValveProgressivRetract 132;
BA_ "DDI" SG_ 2362179200 AuxiliaryValveProgressivExtend 131;
BA_ "DDI" SG_ 2362179200 AuxiliaryValveFloatThreshold 130;
BA_ "DDI" SG_ 2362179200 AuxiliaryValveRampRetractDown 129;
BA_ "DDI" SG_ 2362179200 AuxiliaryValveRampRetractUp 128;
BA_ "DDI" SG_ 2362179200 AuxiliaryValveRampExtendDown 127;
BA_ "DDI" SG_ 2362179200 AuxiliaryValveScalingRetract 125;
BA_ "DDI" SG_ 2362179200 AuxiliaryValveScalingExtend 124;
BA_ "DDI" SG_ 2362179200 AuxiliaryRampExtendUp 126;
BA_ "DDI" SG_ 2362179200 AppRateVolumePerArea_Set 1;
BA_ "DDI" SG_ 2362179200 AppRateVolumePerArea_Act 2;
BA_ "DDI" SG_ 2362179200 AppRateVolumePerArea_Def 3;
BA_ "DDI" SG_ 2362179200 AppRateVolumePerArea_Min 4;
BA_ "DDI" SG_ 2362179200 AppRateVolumePerArea_Max 5;
BA_ "DDI" SG_ 2362179200 AppRateMassPerArea_Set 6;
BA_ "DDI" SG_ 2362179200 AppRateMassPerArea_Act 7;
BA_ "DDI" SG_ 2362179200 AppRateMassPerArea_Def 8;
BA_ "DDI" SG_ 2362179200 AppRateMassPerArea_Min 9;
BA_ "DDI" SG_ 2362179200 AppRateMassPerArea_Max 10;
BA_ "DDI" SG_ 2362179200 AppRateCountPerArea_Set 11;
BA_ "DDI" SG_ 2362179200 AppRateCountPerArea_Act 12;
BA_ "DDI" SG_ 2362179200 AppRateCountPerArea_Def 13;
BA_ "DDI" SG_ 2362179200 AppRateCountPerArea_Min 14;
BA_ "DDI" SG_ 2362179200 AppRateCountPerArea_Max 15;
BA_ "DDI" SG_ 2362179200 SetAppRateDistance_Set 16;
BA_ "DDI" SG_ 2362179200 AppRateDistance_Act 17;
BA_ "DDI" SG_ 2362179200 AppRateDistance_Def 18;
BA_ "DDI" SG_ 2362179200 AppRateDistance_Min 19;
BA_ "DDI" SG_ 2362179200 AppRateDistance_Max 20;
BA_ "DDI" SG_ 2362179200 AppRateVolumePerVolume_Set 21;
BA_ "DDI" SG_ 2362179200 AppRateVolumePerVolume_Act 22;
BA_ "DDI" SG_ 2362179200 AppRateVolumePerVolume_Def 23;
BA_ "DDI" SG_ 2362179200 AppRateVolumePerVolume_Min 24;
BA_ "DDI" SG_ 2362179200 AppRateVolumePerVolume_Max 25;
BA_ "DDI" SG_ 2362179200 AppRateMassPerMass_Set 26;
BA_ "DDI" SG_ 2362179200 AppRateMassPerMass_Act 27;
BA_ "DDI" SG_ 2362179200 AppRateMassPerMass_Def 28;
BA_ "DDI" SG_ 2362179200 AppRateMassPerMass_Min 29;
BA_ "DDI" SG_ 2362179200 AppRateMassPerMass_Max 30;
BA_ "DDI" SG_ 2362179200 AppRateVolumePerMass_Set 31;
BA_ "DDI" SG_ 2362179200 AppRateVolumePerMass_Act 32;
BA_ "DDI" SG_ 2362179200 AppRateVolumePerMass_Def 33;
BA_ "DDI" SG_ 2362179200 AppRateVolumePerMass_Min 34;
BA_ "DDI" SG_ 2362179200 AppRateVolumePerMass_Max 35;
BA_ "DDI" SG_ 2362179200 AppRateVolumePerTime_Set 36;
BA_ "DDI" SG_ 2362179200 AppRateVolumePerTime_Act 37;
BA_ "DDI" SG_ 2362179200 AppRateVolumePerTime_Def 38;
BA_ "DDI" SG_ 2362179200 AppRateVolumePerTime_Min 39;
BA_ "DDI" SG_ 2362179200 AppRateVolumePerTime_Max 40;
BA_ "DDI" SG_ 2362179200 AppRateMassPerTime_Set 41;
BA_ "DDI" SG_ 2362179200 AppRateMassPerTime_Act 42;
BA_ "DDI" SG_ 2362179200 AppRateMassPerTime_Def 43;
BA_ "DDI" SG_ 2362179200 AppRateMassPerTime_Min 44;
BA_ "DDI" SG_ 2362179200 AppRateMassPerTime_Max 45;
BA_ "DDI" SG_ 2362179200 AppRateCountPerTime_Set 46;
BA_ "DDI" SG_ 2362179200 AppRateCountPerTime_Act 47;
BA_ "DDI" SG_ 2362179200 AppRateCountPerTime_Def 48;
BA_ "DDI" SG_ 2362179200 AppRateCountPerTime_Min 49;
BA_ "DDI" SG_ 2362179200 AppRateCountPerTime_Max 50;
BA_ "DDI" SG_ 2362179200 SetTillageDepth_Set 51;
BA_ "DDI" SG_ 2362179200 TillageDepth_Act 52;
BA_ "DDI" SG_ 2362179200 TillageDepth_Def 53;
BA_ "DDI" SG_ 2362179200 TillageDepth_Min 54;
BA_ "DDI" SG_ 2362179200 TillageDepth_Max 55;
BA_ "DDI" SG_ 2362179200 SeedingDeph_Set 56;
BA_ "DDI" SG_ 2362179200 SeedingDeph_Act 57;
BA_ "DDI" SG_ 2362179200 SeedingDeph_Def 58;
BA_ "DDI" SG_ 2362179200 SeedingDeph_Min 59;
BA_ "DDI" SG_ 2362179200 SeedingDeph_Max 60;
BA_ "DDI" SG_ 2362179200 WorkingHeight_Set 61;
BA_ "DDI" SG_ 2362179200 WorkingHeight_Act 62;
BA_ "DDI" SG_ 2362179200 WorkingHeight_Def 63;
BA_ "DDI" SG_ 2362179200 WorkingHeight_Min 64;
BA_ "DDI" SG_ 2362179200 WorkingHeight_Max 65;
BA_ "DDI" SG_ 2362179200 WorkingWidth_Set 66;
BA_ "DDI" SG_ 2362179200 WorkingWidth_Act 67;
BA_ "DDI" SG_ 2362179200 WorkingWidth_Def 68;
BA_ "DDI" SG_ 2362179200 WorkingWidth_Min 69;
BA_ "DDI" SG_ 2362179200 WorkingWidth_Max 70;
BA_ "DDI" SG_ 2362179200 ContentAsVolume_Set 71;
BA_ "DDI" SG_ 2362179200 ContentAsVolume_Act 72;
BA_ "DDI" SG_ 2362179200 ContentAsVolume_Max 73;
BA_ "DDI" SG_ 2362179200 ContentAsMass_Set 74;
BA_ "DDI" SG_ 2362179200 ContentAsMass_Act 75;
BA_ "DDI" SG_ 2362179200 ContentAsMass_Max 76;
BA_ "DDI" SG_ 2362179200 ContentAsCount_Set 77;
BA_ "DDI" SG_ 2362179200 ContentAsCount_Act 78;
BA_ "DDI" SG_ 2362179200 ContentAsCount_Max 79;
BA_ "DDI" SG_ 2362179200 AccumulatedAppAsVolume 80;
BA_ "DDI" SG_ 2362179200 AccumulatedAppAsMass 81;
BA_ "DDI" SG_ 2362179200 AccumulatedAppAsCount 82;
BA_ "DDI" SG_ 2362179200 YieldVolumePerArea 83;
BA_ "DDI" SG_ 2362179200 YieldMassPerArea 84;
BA_ "DDI" SG_ 2362179200 YieldCountPerArea 85;
BA_ "DDI" SG_ 2362179200 YieldVolumePerTime 86;
BA_ "DDI" SG_ 2362179200 YieldMassPerTime 87;
BA_ "DDI" SG_ 2362179200 YieldCountPerTime 88;
BA_ "DDI" SG_ 2362179200 AccumulatedYieldAsVolume 89;
BA_ "DDI" SG_ 2362179200 AccumulatedYieldAsMass 90;
BA_ "DDI" SG_ 2362179200 AccumulatedYieldAsCount 91;
BA_ "DDI" SG_ 2362179200 CropYieldLossVolumePerArea 92;
BA_ "DDI" SG_ 2362179200 CropYieldLossMassPerArea 93;
BA_ "DDI" SG_ 2362179200 CropYieldLossCountPerArea 94;
BA_ "DDI" SG_ 2362179200 CropYieldLossVolumePerTime 95;
BA_ "DDI" SG_ 2362179200 CropYieldLossMassPerTime 96;
BA_ "DDI" SG_ 2362179200 CropYieldLossCountPerTime 97;
BA_ "DDI" SG_ 2362179200 CropYieldLoss 98;
BA_ "DDI" SG_ 2362179200 MoistureInCropYield 99;
BA_ "DDI" SG_ 2362179200 DirtMaterialInCropYield 100;
BA_ "DDI" SG_ 2362179200 BaleWidth_Set 101;
BA_ "DDI" SG_ 2362179200 BaleWidth_Act 102;
BA_ "DDI" SG_ 2362179200 BaleWidth_Def 103;
BA_ "DDI" SG_ 2362179200 BaleWidth_Min 104;
BA_ "DDI" SG_ 2362179200 BaleWidth_Max 105;
BA_ "DDI" SG_ 2362179200 BaleHeight_Set 106;
BA_ "DDI" SG_ 2362179200 BaleHeight_Act 107;
BA_ "DDI" SG_ 2362179200 BaleHeight_Def 108;
BA_ "DDI" SG_ 2362179200 BaleHeight_Min 109;
BA_ "DDI" SG_ 2362179200 BaleHeight_Max 110;
BA_ "DDI" SG_ 2362179200 BaleSize_Set 111;
BA_ "DDI" SG_ 2362179200 BaleSize_Act 112;
BA_ "DDI" SG_ 2362179200 BaleSize_Def 113;
BA_ "DDI" SG_ 2362179200 BaleSize_Min 114;
BA_ "DDI" SG_ 2362179200 BaleSize_Max 115;
BA_ "DDI" SG_ 2362179200 AccumulatedArea 116;
BA_ "DDI" SG_ 2362179200 AccumulatedDistanceInWork 117;
BA_ "DDI" SG_ 2362179200 AccumulatedDistanceOutWork 118;
BA_ "DDI" SG_ 2362179200 AccumulatedTimeInWork 119;
BA_ "DDI" SG_ 2362179200 AccumulatedTimeOutWork 120;
BA_ "DDI" SG_ 2362179200 PrdoucDensityMassPerArea 121;
BA_ "DDI" SG_ 2362179200 PrdoucDensityMassPerCount 122;
BA_ "DDI" SG_ 2362179200 PrdoucDensityVolumePerCount 123;
BA_ "SigType" SG_ 2362179319 ObjectIdOfFaultyObject 1;
BA_ "SigType" SG_ 2362179319 ParentObjectIdOfFaultyObject 1;
BA_ "SigType" SG_ 2362179319 TemperatureUnits 4;
BA_ "SigType" SG_ 2362179319 PressureUnits 4;
BA_ "SigType" SG_ 2362179319 ForceUnits 4;
BA_ "SigType" SG_ 2362179319 UnitsSystem 4;
BA_ "SigType" SG_ 2362179319 DistanceUnitCmd 4;
BA_ "SPN" SG_ 2362179319 DistanceUnitCmd 2414;
BA_ "SigType" SG_ 2362179319 AreaUnitCmd 4;
BA_ "SPN" SG_ 2362179319 AreaUnitCmd 2415;
BA_ "SigType" SG_ 2362179319 VolumeUnitCmd 4;
BA_ "SPN" SG_ 2362179319 VolumeUnitCmd 2416;
BA_ "SigType" SG_ 2362179319 MassUnitCmd 4;
BA_ "SPN" SG_ 2362179319 MassUnitCmd 2417;
BA_ "SigType" SG_ 2362179319 DateFormatCmd 1;
BA_ "SPN" SG_ 2362179319 DateFormatCmd 2412;
BA_ "SigType" SG_ 2362179319 DecimalSymbolCmd 4;
BA_ "SPN" SG_ 2362179319 DecimalSymbolCmd 2411;
BA_ "SigType" SG_ 2362179319 TimeFormatCmd 4;
BA_ "SPN" SG_ 2362179319 TimeFormatCmd 2413;
BA_ "SigType" SG_ 2362179319 LanguageCodeCmd 3;
BA_ "SPN" SG_ 2362179319 LanguageCodeCmd 2410;
BA_ "DDI" SG_ 2362179319 MinMassPerAreaAppRate 152;
BA_ "DDI" SG_ 2362179319 RequestDefaultProcessData 57343;
BA_ "DDI" SG_ 2362179319 AreaPerTimeCapacity 151;
BA_ "DDI" SG_ 2362179319 FuelConsumptionPerArea 150;
BA_ "DDI" SG_ 2362179319 FuelConsumptionPerTime 149;
BA_ "DDI" SG_ 2362179319 TotalFuelConsumption 148;
BA_ "DDI" SG_ 2362179319 LogCount 147;
BA_ "DDI" SG_ 2362179319 PitchAngle 146;
BA_ "DDI" SG_ 2362179319 RollAngle 145;
BA_ "DDI" SG_ 2362179319 YawAngle 144;
BA_ "DDI" SG_ 2362179319 ActualValueTimeLatency 143;
BA_ "DDI" SG_ 2362179319 SetpointTimeLatency 142;
BA_ "DDI" SG_ 2362179319 WorkState 141;
BA_ "DDI" SG_ 2362179319 PercentageAppRateSetpoint 140;
BA_ "DDI" SG_ 2362179319 DeviceCountCapacity 139;
BA_ "DDI" SG_ 2362179319 DeviceMassCapacity 138;
BA_ "DDI" SG_ 2362179319 DeviceVolumeCapacity 137;
BA_ "DDI" SG_ 2362179319 DeviceElementOffsetZ 136;
BA_ "DDI" SG_ 2362179319 DeviceElementOffsetY 135;
BA_ "DDI" SG_ 2362179319 DeviceElementOffsetX 134;
BA_ "DDI" SG_ 2362179319 AuxiliaryValveInvertPorts 133;
BA_ "DDI" SG_ 2362179319 AuxiliaryValveProgressivRetract 132;
BA_ "DDI" SG_ 2362179319 AuxiliaryValveProgressivExtend 131;
BA_ "DDI" SG_ 2362179319 AuxiliaryValveFloatThreshold 130;
BA_ "DDI" SG_ 2362179319 AuxiliaryValveRampRetractDown 129;
BA_ "DDI" SG_ 2362179319 AuxiliaryValveRampRetractUp 128;
BA_ "DDI" SG_ 2362179319 AuxiliaryValveRampExtendDown 127;
BA_ "DDI" SG_ 2362179319 AuxiliaryValveScalingRetract 125;
BA_ "DDI" SG_ 2362179319 AuxiliaryValveScalingExtend 124;
BA_ "DDI" SG_ 2362179319 AuxiliaryRampExtendUp 126;
BA_ "DDI" SG_ 2362179319 AppRateVolumePerArea_Set 1;
BA_ "DDI" SG_ 2362179319 AppRateVolumePerArea_Act 2;
BA_ "DDI" SG_ 2362179319 AppRateVolumePerArea_Def 3;
BA_ "DDI" SG_ 2362179319 AppRateVolumePerArea_Min 4;
BA_ "DDI" SG_ 2362179319 AppRateVolumePerArea_Max 5;
BA_ "DDI" SG_ 2362179319 AppRateMassPerArea_Set 6;
BA_ "DDI" SG_ 2362179319 AppRateMassPerArea_Act 7;
BA_ "DDI" SG_ 2362179319 AppRateMassPerArea_Def 8;
BA_ "DDI" SG_ 2362179319 AppRateMassPerArea_Min 9;
BA_ "DDI" SG_ 2362179319 AppRateMassPerArea_Max 10;
BA_ "DDI" SG_ 2362179319 AppRateCountPerArea_Set 11;
BA_ "DDI" SG_ 2362179319 AppRateCountPerArea_Act 12;
BA_ "DDI" SG_ 2362179319 AppRateCountPerArea_Def 13;
BA_ "DDI" SG_ 2362179319 AppRateCountPerArea_Min 14;
BA_ "DDI" SG_ 2362179319 AppRateCountPerArea_Max 15;
BA_ "DDI" SG_ 2362179319 SetAppRateDistance_Set 16;
BA_ "DDI" SG_ 2362179319 AppRateDistance_Act 17;
BA_ "DDI" SG_ 2362179319 AppRateDistance_Def 18;
BA_ "DDI" SG_ 2362179319 AppRateDistance_Min 19;
BA_ "DDI" SG_ 2362179319 AppRateDistance_Max 20;
BA_ "DDI" SG_ 2362179319 AppRateVolumePerVolume_Set 21;
BA_ "DDI" SG_ 2362179319 AppRateVolumePerVolume_Act 22;
BA_ "DDI" SG_ 2362179319 AppRateVolumePerVolume_Def 23;
BA_ "DDI" SG_ 2362179319 AppRateVolumePerVolume_Min 24;
BA_ "DDI" SG_ 2362179319 AppRateVolumePerVolume_Max 25;
BA_ "DDI" SG_ 2362179319 AppRateMassPerMass_Set 26;
BA_ "DDI" SG_ 2362179319 AppRateMassPerMass_Act 27;
BA_ "DDI" SG_ 2362179319 AppRateMassPerMass_Def 28;
BA_ "DDI" SG_ 2362179319 AppRateMassPerMass_Min 29;
BA_ "DDI" SG_ 2362179319 AppRateMassPerMass_Max 30;
BA_ "DDI" SG_ 2362179319 AppRateVolumePerMass_Set 31;
BA_ "DDI" SG_ 2362179319 AppRateVolumePerMass_Act 32;
BA_ "DDI" SG_ 2362179319 AppRateVolumePerMass_Def 33;
BA_ "DDI" SG_ 2362179319 AppRateVolumePerMass_Min 34;
BA_ "DDI" SG_ 2362179319 AppRateVolumePerMass_Max 35;
BA_ "DDI" SG_ 2362179319 AppRateVolumePerTime_Set 36;
BA_ "DDI" SG_ 2362179319 AppRateVolumePerTime_Act 37;
BA_ "DDI" SG_ 2362179319 AppRateVolumePerTime_Def 38;
BA_ "DDI" SG_ 2362179319 AppRateVolumePerTime_Min 39;
BA_ "DDI" SG_ 2362179319 AppRateVolumePerTime_Max 40;
BA_ "DDI" SG_ 2362179319 AppRateMassPerTime_Set 41;
BA_ "DDI" SG_ 2362179319 AppRateMassPerTime_Act 42;
BA_ "DDI" SG_ 2362179319 AppRateMassPerTime_Def 43;
BA_ "DDI" SG_ 2362179319 AppRateMassPerTime_Min 44;
BA_ "DDI" SG_ 2362179319 AppRateMassPerTime_Max 45;
BA_ "DDI" SG_ 2362179319 AppRateCountPerTime_Set 46;
BA_ "DDI" SG_ 2362179319 AppRateCountPerTime_Act 47;
BA_ "DDI" SG_ 2362179319 AppRateCountPerTime_Def 48;
BA_ "DDI" SG_ 2362179319 AppRateCountPerTime_Min 49;
BA_ "DDI" SG_ 2362179319 AppRateCountPerTime_Max 50;
BA_ "DDI" SG_ 2362179319 SetTillageDepth_Set 51;
BA_ "DDI" SG_ 2362179319 TillageDepth_Act 52;
BA_ "DDI" SG_ 2362179319 TillageDepth_Def 53;
BA_ "DDI" SG_ 2362179319 TillageDepth_Min 54;
BA_ "DDI" SG_ 2362179319 TillageDepth_Max 55;
BA_ "DDI" SG_ 2362179319 SeedingDeph_Set 56;
BA_ "DDI" SG_ 2362179319 SeedingDeph_Act 57;
BA_ "DDI" SG_ 2362179319 SeedingDeph_Def 58;
BA_ "DDI" SG_ 2362179319 SeedingDeph_Min 59;
BA_ "DDI" SG_ 2362179319 SeedingDeph_Max 60;
BA_ "DDI" SG_ 2362179319 WorkingHeight_Set 61;
BA_ "DDI" SG_ 2362179319 WorkingHeight_Act 62;
BA_ "DDI" SG_ 2362179319 WorkingHeight_Def 63;
BA_ "DDI" SG_ 2362179319 WorkingHeight_Min 64;
BA_ "DDI" SG_ 2362179319 WorkingHeight_Max 65;
BA_ "DDI" SG_ 2362179319 WorkingWidth_Set 66;
BA_ "DDI" SG_ 2362179319 WorkingWidth_Act 67;
BA_ "DDI" SG_ 2362179319 WorkingWidth_Def 68;
BA_ "DDI" SG_ 2362179319 WorkingWidth_Min 69;
BA_ "DDI" SG_ 2362179319 WorkingWidth_Max 70;
BA_ "DDI" SG_ 2362179319 ContentAsVolume_Set 71;
BA_ "DDI" SG_ 2362179319 ContentAsVolume_Act 72;
BA_ "DDI" SG_ 2362179319 ContentAsVolume_Max 73;
BA_ "DDI" SG_ 2362179319 ContentAsMass_Set 74;
BA_ "DDI" SG_ 2362179319 ContentAsMass_Act 75;
BA_ "DDI" SG_ 2362179319 ContentAsMass_Max 76;
BA_ "DDI" SG_ 2362179319 ContentAsCount_Set 77;
BA_ "DDI" SG_ 2362179319 ContentAsCount_Act 78;
BA_ "DDI" SG_ 2362179319 ContentAsCount_Max 79;
BA_ "DDI" SG_ 2362179319 AccumulatedAppAsVolume 80;
BA_ "DDI" SG_ 2362179319 AccumulatedAppAsMass 81;
BA_ "DDI" SG_ 2362179319 AccumulatedAppAsCount 82;
BA_ "DDI" SG_ 2362179319 YieldVolumePerArea 83;
BA_ "DDI" SG_ 2362179319 YieldMassPerArea 84;
BA_ "DDI" SG_ 2362179319 YieldCountPerArea 85;
BA_ "DDI" SG_ 2362179319 YieldVolumePerTime 86;
BA_ "DDI" SG_ 2362179319 YieldMassPerTime 87;
BA_ "DDI" SG_ 2362179319 YieldCountPerTime 88;
BA_ "DDI" SG_ 2362179319 AccumulatedYieldAsVolume 89;
BA_ "DDI" SG_ 2362179319 AccumulatedYieldAsMass 90;
BA_ "DDI" SG_ 2362179319 AccumulatedYieldAsCount 91;
BA_ "DDI" SG_ 2362179319 CropYieldLossVolumePerArea 92;
BA_ "DDI" SG_ 2362179319 CropYieldLossMassPerArea 93;
BA_ "DDI" SG_ 2362179319 CropYieldLossCountPerArea 94;
BA_ "DDI" SG_ 2362179319 CropYieldLossVolumePerTime 95;
BA_ "DDI" SG_ 2362179319 CropYieldLossMassPerTime 96;
BA_ "DDI" SG_ 2362179319 CropYieldLossCountPerTime 97;
BA_ "DDI" SG_ 2362179319 CropYieldLoss 98;
BA_ "DDI" SG_ 2362179319 MoistureInCropYield 99;
BA_ "DDI" SG_ 2362179319 DirtMaterialInCropYield 100;
BA_ "DDI" SG_ 2362179319 BaleWidth_Set 101;
BA_ "DDI" SG_ 2362179319 BaleWidth_Act 102;
BA_ "DDI" SG_ 2362179319 BaleWidth_Def 103;
BA_ "DDI" SG_ 2362179319 BaleWidth_Min 104;
BA_ "DDI" SG_ 2362179319 BaleWidth_Max 105;
BA_ "DDI" SG_ 2362179319 BaleHeight_Set 106;
BA_ "DDI" SG_ 2362179319 BaleHeight_Act 107;
BA_ "DDI" SG_ 2362179319 BaleHeight_Def 108;
BA_ "DDI" SG_ 2362179319 BaleHeight_Min 109;
BA_ "DDI" SG_ 2362179319 BaleHeight_Max 110;
BA_ "DDI" SG_ 2362179319 BaleSize_Set 111;
BA_ "DDI" SG_ 2362179319 BaleSize_Act 112;
BA_ "DDI" SG_ 2362179319 BaleSize_Def 113;
BA_ "DDI" SG_ 2362179319 BaleSize_Min 114;
BA_ "DDI" SG_ 2362179319 BaleSize_Max 115;
BA_ "DDI" SG_ 2362179319 AccumulatedArea 116;
BA_ "DDI" SG_ 2362179319 AccumulatedDistanceInWork 117;
BA_ "DDI" SG_ 2362179319 AccumulatedDistanceOutWork 118;
BA_ "DDI" SG_ 2362179319 AccumulatedTimeInWork 119;
BA_ "DDI" SG_ 2362179319 AccumulatedTimeOutWork 120;
BA_ "DDI" SG_ 2362179319 PrdoucDensityMassPerArea 121;
BA_ "DDI" SG_ 2362179319 PrdoucDensityMassPerCount 122;
BA_ "DDI" SG_ 2362179319 PrdoucDensityVolumePerCount 123;
VAL_ 2365458942 LimitStatusReporting 1 "Facility available" 0 "Facility not available" ;
VAL_ 2365458942 SpeedInfo_EngineSpeed 0 "EngineSpeedInfoNotAvailable" 1 "EngineSpeedInfoAvailable" ;
VAL_ 2365458942 SpeedInfo_GroundBasedSpeed 0 "GndBasedSpeedInfoNotAvailable" 1 "GndBasedSpeedInfoAvailable" ;
VAL_ 2365458942 SpeedInfo_WheelBasedSpeed 0 "WheelBasedSpeedInfoNotAvailable" 1 "WheelBasedSpeedInfoAvailable" ;
VAL_ 2365458942 PowerMgt_MaintainPower 0 "MainPwrMgtNotAvailable" 1 "MainPwrMgtAvailable" ;
VAL_ 2365458942 PowerMgt_MaxTimeTractorPower 0 "MaxTimeTractorPwrMgtNotAvailable" 1 "MaxTimeTractorPwrMgtAvailable" ;
VAL_ 2365458942 PowerMgt_KeySwitch 0 "KeySwitchPwrMgtNotAvailable" 1 "KeySwitchPwrMgtAvailable" ;
VAL_ 2365458942 TractorClass 0 "TECU_Class_1" 1 "TECU_Class_2" 2 "TECU_Class_3" 3 "NotAvailable" ;
VAL_ 2365458942 LanguageCmdStorageInTractorECU 0 "LangCmdNotAvailableInTractorECU" 1 "LangCmdAvailableInTractorECU" ;
VAL_ 2365458942 Lighting_MinimalSet 0 "MinSetNotAvailable" 1 "MinSetAvailable" ;
VAL_ 2365458942 PTOInfo_RearShaftEngagement 0 "PTOInfo_RearShaftEgtNotAvailable" 1 "PTOInfo_RearShaftEgtAvailable" ;
VAL_ 2365458942 PTOInfo_RearShaftSpeed 0 "PTOInfo_RearShaftSpdNotAvailable" 1 "PTOInfo_RearShaftSpdAvailable" ;
VAL_ 2365458942 HitchInfo_RearInWork 0 "HitchInfo_RearInWorkNotAvailable" 1 "HitchInfo_RearInWorkAvailable" ;
VAL_ 2365458942 HitchInfo_RearPosition 0 "HitchInfo_RearInPosNotAvailable" 1 "HitchInfo_RearInPosAvailable" ;
VAL_ 2365458942 EstimatedOrMeasuredAuxValveState 0 "EstOrMeasAuxValStatNotAvailable" 1 "EstOrMeasAuxValStatAvailable" ;
VAL_ 2365458942 Light_FullImplLightingMessageSet 0 "FullImplLightMsgSetNotAvailable" 1 "FullImplLightMsgSetAvailable" ;
VAL_ 2365458942 AddHitchParameter_RearDraft 0 "HitchInfo_RearDraftNotAvailable" 1 "HitchInfo_RearDraftAvailable" ;
VAL_ 2365458942 SpeedAndDist_WheelBasedDirection 0 "WheelBasedDirectionNotAvailable" 1 "WheelBasedDirectionAvailable" ;
VAL_ 2365458942 SpeedAndDist_WheelBasedDistance 0 "WheelBasedDistanceNotAvailable" 1 "WheelBasedDistanceAvailable" ;
VAL_ 2365458942 SpeedAndDist_GndBasedDirection 0 "GndBasedDirectionNotAvailable" 1 "GndBasedDirectionAvailable" ;
VAL_ 2365458942 SpeedAndDist_GndBasedDistance 0 "GndBasedDistanceNotAvailable" 1 "GndBasedDistanceAvailable" ;
VAL_ 2365458942 TimeDate 0 "TimeAndDateNotAvailable" 1 "TimeAndDateAvailable" ;
VAL_ 2365458942 AuxiliaryValveCmd 0 "AuxiliaryValveCmdsNotAvailable" 1 "AuxiliaryValveCmdsAvailable" ;
VAL_ 2365458942 PTOCmd_RearPTOEngagementCmd 0 "RearPTOEgtCmdNotAvailable" 1 "RearPTOEgtCmdAvailable" ;
VAL_ 2365458942 PTOCmd_RearPTOSpeedCmd 0 "RearPTOSpeedCmdNotAvailable" 1 "RearPTOSpeedCmdAvailable" ;
VAL_ 2365458942 HitchCmd_RearHitchPosition 0 "HitchRearPosNotAvailable" 1 "HitchRearPosAvailable" ;
VAL_ 2365458942 NavigPseudorangeNoiseStatistic 0 "NavigPsdoNoiseStatNotAvailable" 1 "NavigPsdoNoiseStatAvailable" ;
VAL_ 2365458942 NavigSystemPositionData 0 "NavigSysPosDataNotAvailable" 1 "NavigSysPosDataAvailable" ;
VAL_ 2365458942 NavigSystemHighOutputPosition 0 "NavigSysHOutPosDataNotAvailable" 1 "NavigSysHOutPosDataAvailable" ;
VAL_ 2365458942 PTOCmd_FrontPTOEngagementCmd 0 "FrontPTOEgtCmdNotAvailable" 1 "FrontPTOEgtCmdAvailable" ;
VAL_ 2365458942 PTOCmd_FrontPTOSpeedCmd 0 "FrontPTOSpeedCmdNotAvailable" 1 "FrontPTOSpeedCmdAvailable" ;
VAL_ 2365458942 HitchCmd_FrontHitchPosition 0 "FrontHitchPosNotAvailable" 1 "FrontHitchPosAvailable" ;
VAL_ 2365458942 AddHitchParameter__FrontDraft 0 "FrontDraftNotAvailable" 1 "FrontDraftAvailable" ;
VAL_ 2365458942 PTOInfo_FrontShaftEngagement 0 "FrontShaftEgtNotAvailable" 1 "FrontShaftEgtAvailable" ;
VAL_ 2365458942 PTOInfo_FrontShaftSpeed 0 "FrontShaftSpeedNotAvailable" 1 "FrontShaftSpeedAvailable" ;
VAL_ 2365458942 HitchInfo_FrontInWork 0 "FrontInWorkNotAvailable" 1 "FrontInWorkAvailable" ;
VAL_ 2365458942 HitchInfo_FrontPosition 0 "FrontPositionNotAvailable" 1 "FrontPositionAvailable" ;
VAL_ 2566787070 TimeFormatCmd 0 "Hour24" 1 "Hour12" 3 "NoAction" ;
VAL_ 2566787070 DecimalSymbolCmd 0 "CommaIsUsed" 1 "PointIsUsed" 3 "NoAction" ;
VAL_ 2566787070 DateFormatCmd 0 "ddmmyyyy" 1 "ddyyyymm" 2 "mmyyyydd" 3 "mmddyyyy" 4 "yyyymmdd" 5 "yyyyddmm" ;
VAL_ 2566787070 MassUnitCmd 0 "Metric" 1 "Imperial" 2 "TonsPounds" 3 "NoAction" ;
VAL_ 2566787070 VolumeUnitCmd 0 "Metric" 1 "Imperial" 2 "US" 3 "NoAction" ;
VAL_ 2566787070 AreaUnitCmd 0 "Metric" 1 "Imperial" 3 "NoAction" ;
VAL_ 2566787070 DistanceUnitCmd 0 "Metric" 1 "Imperial" 3 "NoAction" ;
VAL_ 2566787070 UnitsSystem 0 "Metric" 1 "Imperial" 2 "US" 3 "NoAction" ;
VAL_ 2566787070 ForceUnits 0 "Metric" 1 "Imperial" 2 "Reserved" 3 "NoAction" ;
VAL_ 2566787070 PressureUnits 0 "Metric" 1 "Imperial" 2 "Reserved" 3 "NoAction" ;
VAL_ 2566787070 TemperatureUnits 0 "Metric" 1 "Imperial" 2 "Reserved" 3 "NoAction" ;
VAL_ 2362179200 ErrorCodeProcessData6 0 "NoError" 1 "InvalidIntervalOrThreshold" ;
VAL_ 2362179200 ErrorCodeProcessData5 0 "NoError" 1 "ProcessDataNotSetable" ;
VAL_ 2362179200 ErrorCodeProcessData4 0 "NoError" 1 "TriggerMethodNotSupported" ;
VAL_ 2362179200 ErrorCodeProcessData3 0 "NoError" 1 "DDINotSupportedByElement" ;
VAL_ 2362179200 ErrorCodeProcessData2 0 "NoError" 1 "InvalidElementNumber" ;
VAL_ 2362179200 ErrorCodeProcessData1 0 "NoError" 1 "CommandNotSupported" ;
VAL_ 2362179200 ErrorCodeChangeDesignator 1 "Error" 0 "Success" ;
VAL_ 2362179200 ErrorCodeObjectPoolDelete 1 "Error" 0 "Success" ;
VAL_ 2362179200 ErrorCodeObjPool4 1 "ObjectPoolWasDeleted" 0 "NoError" ;
VAL_ 2362179200 ErrorCodeObjPool3 1 "GeneralError" 0 "NoError" ;
VAL_ 2362179200 ErrorCodeObjPool2 1 "UnknownObjectReference" 0 "NoError" ;
VAL_ 2362179200 ErrorCodeObjPool1 1 "MethodOrAttributeNotSupported" 0 "NoError" ;
VAL_ 2362179200 ErrorCodeObjPoolActiveResp3 1 "GeneralError" 0 "NoError" ;
VAL_ 2362179200 ErrorCodeObjPoolActiveResp2 1 "TaskControllerRanOutOfMemory" 0 "NoError" ;
VAL_ 2362179200 ErrorCodeObjPoolActiveResp1 1 "ErrorsInTheObjectPool" 0 "NoError" ;
VAL_ 2362179200 ErrorCodeObjPoolTransfer 2 "GeneralError" 1 "TaskControllerRanOutOfMemory" 0 "NoError" ;
VAL_ 2362179200 Status 1 "NotEnoughMemoryAvailable" 0 "EnoughMemoryAvailable" ;
VAL_ 2362179200 TemperatureUnits 0 "Metric" 1 "Imperial" 2 "Reserved" 3 "NoAction" ;
VAL_ 2362179200 PressureUnits 0 "Metric" 1 "Imperial" 2 "Reserved" 3 "NoAction" ;
VAL_ 2362179200 ForceUnits 0 "Metric" 1 "Imperial" 2 "Reserved" 3 "NoAction" ;
VAL_ 2362179200 UnitsSystem 0 "Metric" 1 "Imperial" 2 "US" 3 "NoAction" ;
VAL_ 2362179200 DistanceUnitCmd 0 "Metric" 1 "Imperial" 3 "NoAction" ;
VAL_ 2362179200 AreaUnitCmd 0 "Metric" 1 "Imperial" 3 "NoAction" ;
VAL_ 2362179200 VolumeUnitCmd 0 "Metric" 1 "Imperial" 2 "US" 3 "NoAction" ;
VAL_ 2362179200 MassUnitCmd 0 "Metric" 1 "Imperial" 2 "TonsPounds" 3 "NoAction" ;
VAL_ 2362179200 DateFormatCmd 0 "ddmmyyyy" 1 "ddyyyymm" 2 "mmyyyydd" 3 "mmddyyyy" 4 "yyyymmdd" 5 "yyyyddmm" ;
VAL_ 2362179200 DecimalSymbolCmd 0 "CommaIsUsed" 1 "PointIsUsed" 3 "NoAction" ;
VAL_ 2362179200 TimeFormatCmd 0 "Hour24" 1 "Hour12" 3 "NoAction" ;
VAL_ 2362179200 DeviceDescriptionMsgType 13 "ChangeDesignatorResponse" 12 "ChangeDesignator" 11 "ObjectPoolDeleteResponse" 10 "ObjectPoolDelete" 9 "ObjectPoolActivateResponse" 8 "ObjectPoolActivate" 7 "ObjectPoolTransferResponse" 6 "ObjectPoolTransfer" 5 "RequestObjectPoolTransferResp" 4 "RequestObjectPoolTransfer" 3 "LocalizationLabel" 2 "RequestLocalizationLabel" 1 "StructureLabel" 0 "RequestStructureLabel" ;
VAL_ 2362179200 TechnicalDataMsgType 1 "ParameterVersion" 0 "ParameterRequestVersion" ;
VAL_ 2362179200 Command 0 "TechnicalData" 1 "DeviceDescription" 2 "RequestValue" 3 "ValueCommand" 4 "TimeInterval" 5 "DistanceInterval" 6 "MinWithinThreshold" 7 "MaxWithinThreshold" 8 "ChangeThreshold" 13 "PDNACK" 14 "TaskControllerStatus" 15 "WorkingSetTask" ;
VAL_ 2362179319 ErrorCodeProcessData6 0 "NoError" 1 "InvalidIntervalOrThreshold" ;
VAL_ 2362179319 ErrorCodeProcessData5 0 "NoError" 1 "ProcessDataNotSetable" ;
VAL_ 2362179319 ErrorCodeProcessData4 0 "NoError" 1 "TriggerMethodNotSupported" ;
VAL_ 2362179319 ErrorCodeProcessData3 0 "NoError" 1 "DDINotSupportedByElement" ;
VAL_ 2362179319 ErrorCodeProcessData2 0 "NoError" 1 "InvalidElementNumber" ;
VAL_ 2362179319 ErrorCodeProcessData1 0 "NoError" 1 "CommandNotSupported" ;
VAL_ 2362179319 ErrorCodeChangeDesignator 1 "Error" 0 "Success" ;
VAL_ 2362179319 ErrorCodeObjectPoolDelete 1 "Error" 0 "Success" ;
VAL_ 2362179319 ErrorCodeObjPool4 1 "ObjectPoolWasDeleted" 0 "NoError" ;
VAL_ 2362179319 ErrorCodeObjPool3 1 "GeneralError" 0 "NoError" ;
VAL_ 2362179319 ErrorCodeObjPool2 1 "UnknownObjectReference" 0 "NoError" ;
VAL_ 2362179319 ErrorCodeObjPool1 1 "MethodOrAttributeNotSupported" 0 "NoError" ;
VAL_ 2362179319 ErrorCodeObjPoolActiveResp3 1 "GeneralError" 0 "NoError" ;
VAL_ 2362179319 ErrorCodeObjPoolActiveResp2 1 "TaskControllerRanOutOfMemory" 0 "NoError" ;
VAL_ 2362179319 ErrorCodeObjPoolActiveResp1 1 "ErrorsInTheObjectPool" 0 "NoError" ;
VAL_ 2362179319 ErrorCodeObjPoolTransfer 2 "GeneralError" 1 "TaskControllerRanOutOfMemory" 0 "NoError" ;
VAL_ 2362179319 Status 1 "NotEnoughMemoryAvailable" 0 "EnoughMemoryAvailable" ;
VAL_ 2362179319 TemperatureUnits 0 "Metric" 1 "Imperial" 2 "Reserved" 3 "NoAction" ;
VAL_ 2362179319 PressureUnits 0 "Metric" 1 "Imperial" 2 "Reserved" 3 "NoAction" ;
VAL_ 2362179319 ForceUnits 0 "Metric" 1 "Imperial" 2 "Reserved" 3 "NoAction" ;
VAL_ 2362179319 UnitsSystem 0 "Metric" 1 "Imperial" 2 "US" 3 "NoAction" ;
VAL_ 2362179319 DistanceUnitCmd 0 "Metric" 1 "Imperial" 3 "NoAction" ;
VAL_ 2362179319 AreaUnitCmd 0 "Metric" 1 "Imperial" 3 "NoAction" ;
VAL_ 2362179319 VolumeUnitCmd 0 "Metric" 1 "Imperial" 2 "US" 3 "NoAction" ;
VAL_ 2362179319 MassUnitCmd 0 "Metric" 1 "Imperial" 2 "TonsPounds" 3 "NoAction" ;
VAL_ 2362179319 DateFormatCmd 0 "ddmmyyyy" 1 "ddyyyymm" 2 "mmyyyydd" 3 "mmddyyyy" 4 "yyyymmdd" 5 "yyyyddmm" ;
VAL_ 2362179319 DecimalSymbolCmd 0 "CommaIsUsed" 1 "PointIsUsed" 3 "NoAction" ;
VAL_ 2362179319 TimeFormatCmd 0 "Hour24" 1 "Hour12" 3 "NoAction" ;
VAL_ 2362179319 DeviceDescriptionMsgType 13 "ChangeDesignatorResponse" 12 "ChangeDesignator" 11 "ObjectPoolDeleteResponse" 10 "ObjectPoolDelete" 9 "ObjectPoolActivateResponse" 8 "ObjectPoolActivate" 7 "ObjectPoolTransferResponse" 6 "ObjectPoolTransfer" 5 "RequestObjectPoolTransferResp" 4 "RequestObjectPoolTransfer" 3 "LocalizationLabel" 2 "RequestLocalizationLabel" 1 "StructureLabel" 0 "RequestStructureLabel" ;
VAL_ 2362179319 TechnicalDataMsgType 1 "ParameterVersion" 0 "ParameterRequestVersion" ;
VAL_ 2362179319 Command 0 "TechnicalData" 1 "DeviceDescription" 2 "RequestValue" 3 "ValueCommand" 4 "TimeInterval" 5 "DistanceInterval" 6 "MinWithinThreshold" 7 "MaxWithinThreshold" 8 "ChangeThreshold" 13 "PDNACK" 14 "TaskControllerStatus" 15 "WorkingSetTask" ;

SG_MUL_VAL_ 2362179200 ErrorElementNumber Command 13-13;
SG_MUL_VAL_ 2362179200 ErrorDDI Command 13-13;
SG_MUL_VAL_ 2362179200 ErrorCodeProcessData6 Command 13-13;
SG_MUL_VAL_ 2362179200 ErrorCodeProcessData5 Command 13-13;
SG_MUL_VAL_ 2362179200 ErrorCodeProcessData4 Command 13-13;
SG_MUL_VAL_ 2362179200 ErrorCodeProcessData3 Command 13-13;
SG_MUL_VAL_ 2362179200 ErrorCodeProcessData2 Command 13-13;
SG_MUL_VAL_ 2362179200 ErrorCodeProcessData1 Command 13-13;
SG_MUL_VAL_ 2362179200 Status_TotalsActive Command 15-15;
SG_MUL_VAL_ 2362179200 ExecutedCommand Command 14-14;
SG_MUL_VAL_ 2362179200 SourceAddressWSM Command 14-14;
SG_MUL_VAL_ 2362179200 StatusBusyExecuting Command 14-14;
SG_MUL_VAL_ 2362179200 StatusBusyReading Command 14-14;
SG_MUL_VAL_ 2362179200 StatusBusySaving Command 14-14;
SG_MUL_VAL_ 2362179200 StatusTotalsActive Command 14-14;
SG_MUL_VAL_ 2362179200 ObjectIdChanged DeviceDescriptionMsgType 13-13;
SG_MUL_VAL_ 2362179200 DesignatorLength DeviceDescriptionMsgType 12-12;
SG_MUL_VAL_ 2362179200 ObjectIdToChange DeviceDescriptionMsgType 12-12;
SG_MUL_VAL_ 2362179200 ErrorCodeChangeDesignator DeviceDescriptionMsgType 13-13;
SG_MUL_VAL_ 2362179200 ErrorCodeObjectPoolDelete DeviceDescriptionMsgType 11-11;
SG_MUL_VAL_ 2362179200 ErrorCodeObjPool4 DeviceDescriptionMsgType 9-9;
SG_MUL_VAL_ 2362179200 ErrorCodeObjPool3 DeviceDescriptionMsgType 9-9;
SG_MUL_VAL_ 2362179200 ErrorCodeObjPool2 DeviceDescriptionMsgType 9-9;
SG_MUL_VAL_ 2362179200 ErrorCodeObjPool1 DeviceDescriptionMsgType 9-9;
SG_MUL_VAL_ 2362179200 ErrorCodeObjPoolActiveResp3 DeviceDescriptionMsgType 9-9;
SG_MUL_VAL_ 2362179200 ErrorCodeObjPoolActiveResp2 DeviceDescriptionMsgType 9-9;
SG_MUL_VAL_ 2362179200 ErrorCodeObjPoolActiveResp1 DeviceDescriptionMsgType 9-9;
SG_MUL_VAL_ 2362179200 ObjectIdOfFaultyObject DeviceDescriptionMsgType 9-9;
SG_MUL_VAL_ 2362179200 ParentObjectIdOfFaultyObject DeviceDescriptionMsgType 9-9;
SG_MUL_VAL_ 2362179200 ReceivedDataSize DeviceDescriptionMsgType 7-7;
SG_MUL_VAL_ 2362179200 ErrorCodeObjPoolTransfer DeviceDescriptionMsgType 7-7;
SG_MUL_VAL_ 2362179200 Status DeviceDescriptionMsgType 5-5;
SG_MUL_VAL_ 2362179200 RequestTransferDataSize DeviceDescriptionMsgType 4-4;
SG_MUL_VAL_ 2362179200 TemperatureUnits DeviceDescriptionMsgType 2-2, 3-3;
SG_MUL_VAL_ 2362179200 PressureUnits DeviceDescriptionMsgType 2-2, 3-3;
SG_MUL_VAL_ 2362179200 ForceUnits DeviceDescriptionMsgType 2-2, 3-3;
SG_MUL_VAL_ 2362179200 UnitsSystem DeviceDescriptionMsgType 2-2, 3-3;
SG_MUL_VAL_ 2362179200 DistanceUnitCmd DeviceDescriptionMsgType 2-2, 3-3;
SG_MUL_VAL_ 2362179200 AreaUnitCmd DeviceDescriptionMsgType 2-2, 3-3;
SG_MUL_VAL_ 2362179200 VolumeUnitCmd DeviceDescriptionMsgType 2-2, 3-3;
SG_MUL_VAL_ 2362179200 MassUnitCmd DeviceDescriptionMsgType 2-2, 3-3;
SG_MUL_VAL_ 2362179200 DateFormatCmd DeviceDescriptionMsgType 2-2, 3-3;
SG_MUL_VAL_ 2362179200 DecimalSymbolCmd DeviceDescriptionMsgType 2-2, 3-3;
SG_MUL_VAL_ 2362179200 TimeFormatCmd DeviceDescriptionMsgType 2-2, 3-3;
SG_MUL_VAL_ 2362179200 LanguageCodeCmd DeviceDescriptionMsgType 2-2, 3-3;
SG_MUL_VAL_ 2362179200 StructureLabel DeviceDescriptionMsgType 1-1;
SG_MUL_VAL_ 2362179200 DeviceDescriptionMsgType Command 1-1;
SG_MUL_VAL_ 2362179200 VersionNumberISO11783Part10 TechnicalDataMsgType 1-1;
SG_MUL_VAL_ 2362179200 TechnicalDataMsgType Command 0-0;
SG_MUL_VAL_ 2362179200 ElementNumber Command 2-8;
SG_MUL_VAL_ 2362179200 DDI Command 2-8;
SG_MUL_VAL_ 2362179200 MinMassPerAreaAppRate DDI 152-152;
SG_MUL_VAL_ 2362179200 DataDictionaryVersion DDI 0-0;
SG_MUL_VAL_ 2362179200 RequestDefaultProcessData DDI 57343-57343;
SG_MUL_VAL_ 2362179200 AreaPerTimeCapacity DDI 151-151;
SG_MUL_VAL_ 2362179200 FuelConsumptionPerArea DDI 150-150;
SG_MUL_VAL_ 2362179200 FuelConsumptionPerTime DDI 149-149;
SG_MUL_VAL_ 2362179200 TotalFuelConsumption DDI 148-148;
SG_MUL_VAL_ 2362179200 LogCount DDI 147-147;
SG_MUL_VAL_ 2362179200 PitchAngle DDI 146-146;
SG_MUL_VAL_ 2362179200 RollAngle DDI 145-145;
SG_MUL_VAL_ 2362179200 YawAngle DDI 144-144;
SG_MUL_VAL_ 2362179200 ActualValueTimeLatency DDI 143-143;
SG_MUL_VAL_ 2362179200 SetpointTimeLatency DDI 142-142;
SG_MUL_VAL_ 2362179200 WorkState DDI 141-141;
SG_MUL_VAL_ 2362179200 PercentageAppRateSetpoint DDI 140-140;
SG_MUL_VAL_ 2362179200 DeviceCountCapacity DDI 139-139;
SG_MUL_VAL_ 2362179200 DeviceMassCapacity DDI 138-138;
SG_MUL_VAL_ 2362179200 DeviceVolumeCapacity DDI 137-137;
SG_MUL_VAL_ 2362179200 DeviceElementOffsetZ DDI 136-136;
SG_MUL_VAL_ 2362179200 DeviceElementOffsetY DDI 135-135;
SG_MUL_VAL_ 2362179200 DeviceElementOffsetX DDI 134-134;
SG_MUL_VAL_ 2362179200 AuxiliaryValveInvertPorts DDI 133-133;
SG_MUL_VAL_ 2362179200 AuxiliaryValveProgressivRetract DDI 132-132;
SG_MUL_VAL_ 2362179200 AuxiliaryValveProgressivExtend DDI 131-131;
SG_MUL_VAL_ 2362179200 AuxiliaryValveFloatThreshold DDI 130-130;
SG_MUL_VAL_ 2362179200 AuxiliaryValveRampRetractDown DDI 129-129;
SG_MUL_VAL_ 2362179200 AuxiliaryValveRampRetractUp DDI 128-128;
SG_MUL_VAL_ 2362179200 AuxiliaryValveRampExtendDown DDI 127-127;
SG_MUL_VAL_ 2362179200 AuxiliaryValveScalingRetract DDI 125-125;
SG_MUL_VAL_ 2362179200 AuxiliaryValveScalingExtend DDI 124-124;
SG_MUL_VAL_ 2362179200 AuxiliaryRampExtendUp DDI 126-126;
SG_MUL_VAL_ 2362179200 AppRateVolumePerArea_Set DDI 1-1;
SG_MUL_VAL_ 2362179200 AppRateVolumePerArea_Act DDI 2-2;
SG_MUL_VAL_ 2362179200 AppRateVolumePerArea_Def DDI 3-3;
SG_MUL_VAL_ 2362179200 AppRateVolumePerArea_Min DDI 4-4;
SG_MUL_VAL_ 2362179200 AppRateVolumePerArea_Max DDI 5-5;
SG_MUL_VAL_ 2362179200 AppRateMassPerArea_Set DDI 6-6;
SG_MUL_VAL_ 2362179200 AppRateMassPerArea_Act DDI 7-7;
SG_MUL_VAL_ 2362179200 AppRateMassPerArea_Def DDI 8-8;
SG_MUL_VAL_ 2362179200 AppRateMassPerArea_Min DDI 9-9;
SG_MUL_VAL_ 2362179200 AppRateMassPerArea_Max DDI 10-10;
SG_MUL_VAL_ 2362179200 AppRateCountPerArea_Set DDI 11-11;
SG_MUL_VAL_ 2362179200 AppRateCountPerArea_Act DDI 12-12;
SG_MUL_VAL_ 2362179200 AppRateCountPerArea_Def DDI 13-13;
SG_MUL_VAL_ 2362179200 AppRateCountPerArea_Min DDI 14-14;
SG_MUL_VAL_ 2362179200 AppRateCountPerArea_Max DDI 15-15;
SG_MUL_VAL_ 2362179200 SetAppRateDistance_Set DDI 16-16;
SG_MUL_VAL_ 2362179200 AppRateDistance_Act DDI 17-17;
SG_MUL_VAL_ 2362179200 AppRateDistance_Def DDI 18-18;
SG_MUL_VAL_ 2362179200 AppRateDistance_Min DDI 19-19;
SG_MUL_VAL_ 2362179200 AppRateDistance_Max DDI 20-20;
SG_MUL_VAL_ 2362179200 AppRateVolumePerVolume_Set DDI 21-21;
SG_MUL_VAL_ 2362179200 AppRateVolumePerVolume_Act DDI 22-22;
SG_MUL_VAL_ 2362179200 AppRateVolumePerVolume_Def DDI 23-23;
SG_MUL_VAL_ 2362179200 AppRateVolumePerVolume_Min DDI 24-24;
SG_MUL_VAL_ 2362179200 AppRateVolumePerVolume_Max DDI 25-25;
SG_MUL_VAL_ 2362179200 AppRateMassPerMass_Set DDI 26-26;
SG_MUL_VAL_ 2362179200 AppRateMassPerMass_Act DDI 27-27;
SG_MUL_VAL_ 2362179200 AppRateMassPerMass_Def DDI 28-28;
SG_MUL_VAL_ 2362179200 AppRateMassPerMass_Min DDI 29-29;
SG_MUL_VAL_ 2362179200 AppRateMassPerMass_Max DDI 30-30;
SG_MUL_VAL_ 2362179200 AppRateVolumePerMass_Set DDI 31-31;
SG_MUL_VAL_ 2362179200 AppRateVolumePerMass_Act DDI 32-32;
SG_MUL_VAL_ 2362179200 AppRateVolumePerMass_Def DDI 33-33;
SG_MUL_VAL_ 2362179200 AppRateVolumePerMass_Min DDI 34-34;
SG_MUL_VAL_ 2362179200 AppRateVolumePerMass_Max DDI 35-35;
SG_MUL_VAL_ 2362179200 AppRateVolumePerTime_Set DDI 36-36;
SG_MUL_VAL_ 2362179200 AppRateVolumePerTime_Act DDI 37-37;
SG_MUL_VAL_ 2362179200 AppRateVolumePerTime_Def DDI 38-38;
SG_MUL_VAL_ 2362179200 AppRateVolumePerTime_Min DDI 39-39;
SG_MUL_VAL_ 2362179200 AppRateVolumePerTime_Max DDI 40-40;
SG_MUL_VAL_ 2362179200 AppRateMassPerTime_Set DDI 41-41;
SG_MUL_VAL_ 2362179200 AppRateMassPerTime_Act DDI 42-42;
SG_MUL_VAL_ 2362179200 AppRateMassPerTime_Def DDI 43-43;
SG_MUL_VAL_ 2362179200 AppRateMassPerTime_Min DDI 44-44;
SG_MUL_VAL_ 2362179200 AppRateMassPerTime_Max DDI 45-45;
SG_MUL_VAL_ 2362179200 AppRateCountPerTime_Set DDI 46-46;
SG_MUL_VAL_ 2362179200 AppRateCountPerTime_Act DDI 47-47;
SG_MUL_VAL_ 2362179200 AppRateCountPerTime_Def DDI 48-48;
SG_MUL_VAL_ 2362179200 AppRateCountPerTime_Min DDI 49-49;
SG_MUL_VAL_ 2362179200 AppRateCountPerTime_Max DDI 50-50;
SG_MUL_VAL_ 2362179200 SetTillageDepth_Set DDI 51-51;
SG_MUL_VAL_ 2362179200 TillageDepth_Act DDI 52-52;
SG_MUL_VAL_ 2362179200 TillageDepth_Def DDI 53-53;
SG_MUL_VAL_ 2362179200 TillageDepth_Min DDI 54-54;
SG_MUL_VAL_ 2362179200 TillageDepth_Max DDI 55-55;
SG_MUL_VAL_ 2362179200 SeedingDeph_Set DDI 56-56;
SG_MUL_VAL_ 2362179200 SeedingDeph_Act DDI 57-57;
SG_MUL_VAL_ 2362179200 SeedingDeph_Def DDI 58-58;
SG_MUL_VAL_ 2362179200 SeedingDeph_Min DDI 59-59;
SG_MUL_VAL_ 2362179200 SeedingDeph_Max DDI 60-60;
SG_MUL_VAL_ 2362179200 WorkingHeight_Set DDI 61-61;
SG_MUL_VAL_ 2362179200 WorkingHeight_Act DDI 62-62;
SG_MUL_VAL_ 2362179200 WorkingHeight_Def DDI 63-63;
SG_MUL_VAL_ 2362179200 WorkingHeight_Min DDI 64-64;
SG_MUL_VAL_ 2362179200 WorkingHeight_Max DDI 65-65;
SG_MUL_VAL_ 2362179200 WorkingWidth_Set DDI 66-66;
SG_MUL_VAL_ 2362179200 WorkingWidth_Act DDI 67-67;
SG_MUL_VAL_ 2362179200 WorkingWidth_Def DDI 68-68;
SG_MUL_VAL_ 2362179200 WorkingWidth_Min DDI 69-69;
SG_MUL_VAL_ 2362179200 WorkingWidth_Max DDI 70-70;
SG_MUL_VAL_ 2362179200 ContentAsVolume_Set DDI 71-71;
SG_MUL_VAL_ 2362179200 ContentAsVolume_Act DDI 72-72;
SG_MUL_VAL_ 2362179200 ContentAsVolume_Max DDI 73-73;
SG_MUL_VAL_ 2362179200 ContentAsMass_Set DDI 74-74;
SG_MUL_VAL_ 2362179200 ContentAsMass_Act DDI 75-75;
SG_MUL_VAL_ 2362179200 ContentAsMass_Max DDI 76-76;
SG_MUL_VAL_ 2362179200 ContentAsCount_Set DDI 77-77;
SG_MUL_VAL_ 2362179200 ContentAsCount_Act DDI 78-78;
SG_MUL_VAL_ 2362179200 ContentAsCount_Max DDI 79-79;
SG_MUL_VAL_ 2362179200 AccumulatedAppAsVolume DDI 80-80;
SG_MUL_VAL_ 2362179200 AccumulatedAppAsMass DDI 81-81;
SG_MUL_VAL_ 2362179200 AccumulatedAppAsCount DDI 82-82;
SG_MUL_VAL_ 2362179200 YieldVolumePerArea DDI 83-83;
SG_MUL_VAL_ 2362179200 YieldMassPerArea DDI 84-84;
SG_MUL_VAL_ 2362179200 YieldCountPerArea DDI 85-85;
SG_MUL_VAL_ 2362179200 YieldVolumePerTime DDI 86-86;
SG_MUL_VAL_ 2362179200 YieldMassPerTime DDI 87-87;
SG_MUL_VAL_ 2362179200 YieldCountPerTime DDI 88-88;
SG_MUL_VAL_ 2362179200 AccumulatedYieldAsVolume DDI 89-89;
SG_MUL_VAL_ 2362179200 AccumulatedYieldAsMass DDI 90-90;
SG_MUL_VAL_ 2362179200 AccumulatedYieldAsCount DDI 91-91;
SG_MUL_VAL_ 2362179200 CropYieldLossVolumePerArea DDI 92-92;
SG_MUL_VAL_ 2362179200 CropYieldLossMassPerArea DDI 93-93;
SG_MUL_VAL_ 2362179200 CropYieldLossCountPerArea DDI 94-94;
SG_MUL_VAL_ 2362179200 CropYieldLossVolumePerTime DDI 95-95;
SG_MUL_VAL_ 2362179200 CropYieldLossMassPerTime DDI 96-96;
SG_MUL_VAL_ 2362179200 CropYieldLossCountPerTime DDI 97-97;
SG_MUL_VAL_ 2362179200 CropYieldLoss DDI 98-98;
SG_MUL_VAL_ 2362179200 MoistureInCropYield DDI 99-99;
SG_MUL_VAL_ 2362179200 DirtMaterialInCropYield DDI 100-100;
SG_MUL_VAL_ 2362179200 BaleWidth_Set DDI 101-101;
SG_MUL_VAL_ 2362179200 BaleWidth_Act DDI 102-102;
SG_MUL_VAL_ 2362179200 BaleWidth_Def DDI 103-103;
SG_MUL_VAL_ 2362179200 BaleWidth_Min DDI 104-104;
SG_MUL_VAL_ 2362179200 BaleWidth_Max DDI 105-105;
SG_MUL_VAL_ 2362179200 BaleHeight_Set DDI 106-106;
SG_MUL_VAL_ 2362179200 BaleHeight_Act DDI 107-107;
SG_MUL_VAL_ 2362179200 BaleHeight_Def DDI 108-108;
SG_MUL_VAL_ 2362179200 BaleHeight_Min DDI 109-109;
SG_MUL_VAL_ 2362179200 BaleHeight_Max DDI 110-110;
SG_MUL_VAL_ 2362179200 BaleSize_Set DDI 111-111;
SG_MUL_VAL_ 2362179200 BaleSize_Act DDI 112-112;
SG_MUL_VAL_ 2362179200 BaleSize_Def DDI 113-113;
SG_MUL_VAL_ 2362179200 BaleSize_Min DDI 114-114;
SG_MUL_VAL_ 2362179200 BaleSize_Max DDI 115-115;
SG_MUL_VAL_ 2362179200 AccumulatedArea DDI 116-116;
SG_MUL_VAL_ 2362179200 AccumulatedDistanceInWork DDI 117-117;
SG_MUL_VAL_ 2362179200 AccumulatedDistanceOutWork DDI 118-118;
SG_MUL_VAL_ 2362179200 AccumulatedTimeInWork DDI 119-119;
SG_MUL_VAL_ 2362179200 AccumulatedTimeOutWork DDI 120-120;
SG_MUL_VAL_ 2362179200 PrdoucDensityMassPerArea DDI 121-121;
SG_MUL_VAL_ 2362179200 PrdoucDensityMassPerCount DDI 122-122;
SG_MUL_VAL_ 2362179200 PrdoucDensityVolumePerCount DDI 123-123;
SG_MUL_VAL_ 2362179319 ErrorElementNumber Command 13-13;
SG_MUL_VAL_ 2362179319 ErrorDDI Command 13-13;
SG_MUL_VAL_ 2362179319 ErrorCodeProcessData6 Command 13-13;
SG_MUL_VAL_ 2362179319 ErrorCodeProcessData5 Command 13-13;
SG_MUL_VAL_ 2362179319 ErrorCodeProcessData4 Command 13-13;
SG_MUL_VAL_ 2362179319 ErrorCodeProcessData3 Command 13-13;
SG_MUL_VAL_ 2362179319 ErrorCodeProcessData2 Command 13-13;
SG_MUL_VAL_ 2362179319 ErrorCodeProcessData1 Command 13-13;
SG_MUL_VAL_ 2362179319 Status_TotalsActive Command 15-15;
SG_MUL_VAL_ 2362179319 ExecutedCommand Command 14-14;
SG_MUL_VAL_ 2362179319 SourceAddressWSM Command 14-14;
SG_MUL_VAL_ 2362179319 StatusBusyExecuting Command 14-14;
SG_MUL_VAL_ 2362179319 StatusBusyReading Command 14-14;
SG_MUL_VAL_ 2362179319 StatusBusySaving Command 14-14;
SG_MUL_VAL_ 2362179319 StatusTotalsActive Command 14-14;
SG_MUL_VAL_ 2362179319 ObjectIdChanged DeviceDescriptionMsgType 13-13;
SG_MUL_VAL_ 2362179319 DesignatorLength DeviceDescriptionMsgType 12-12;
SG_MUL_VAL_ 2362179319 ObjectIdToChange DeviceDescriptionMsgType 12-12;
SG_MUL_VAL_ 2362179319 ErrorCodeChangeDesignator DeviceDescriptionMsgType 13-13;
SG_MUL_VAL_ 2362179319 ErrorCodeObjectPoolDelete DeviceDescriptionMsgType 11-11;
SG_MUL_VAL_ 2362179319 ErrorCodeObjPool4 DeviceDescriptionMsgType 9-9;
SG_MUL_VAL_ 2362179319 ErrorCodeObjPool3 DeviceDescriptionMsgType 9-9;
SG_MUL_VAL_ 2362179319 ErrorCodeObjPool2 DeviceDescriptionMsgType 9-9;
SG_MUL_VAL_ 2362179319 ErrorCodeObjPool1 DeviceDescriptionMsgType 9-9;
SG_MUL_VAL_ 2362179319 ErrorCodeObjPoolActiveResp3 DeviceDescriptionMsgType 9-9;
SG_MUL_VAL_ 2362179319 ErrorCodeObjPoolActiveResp2 DeviceDescriptionMsgType 9-9;
SG_MUL_VAL_ 2362179319 ErrorCodeObjPoolActiveResp1 DeviceDescriptionMsgType 9-9;
SG_MUL_VAL_ 2362179319 ObjectIdOfFaultyObject DeviceDescriptionMsgType 9-9;
SG_MUL_VAL_ 2362179319 ParentObjectIdOfFaultyObject DeviceDescriptionMsgType 9-9;
SG_MUL_VAL_ 2362179319 ReceivedDataSize DeviceDescriptionMsgType 7-7;
SG_MUL_VAL_ 2362179319 ErrorCodeObjPoolTransfer DeviceDescriptionMsgType 7-7;
SG_MUL_VAL_ 2362179319 Status DeviceDescriptionMsgType 5-5;
SG_MUL_VAL_ 2362179319 RequestTransferDataSize DeviceDescriptionMsgType 4-4;
SG_MUL_VAL_ 2362179319 TemperatureUnits DeviceDescriptionMsgType 2-2, 3-3;
SG_MUL_VAL_ 2362179319 PressureUnits DeviceDescriptionMsgType 2-2, 3-3;
SG_MUL_VAL_ 2362179319 ForceUnits DeviceDescriptionMsgType 2-2, 3-3;
SG_MUL_VAL_ 2362179319 UnitsSystem DeviceDescriptionMsgType 2-2, 3-3;
SG_MUL_VAL_ 2362179319 DistanceUnitCmd DeviceDescriptionMsgType 2-2, 3-3;
SG_MUL_VAL_ 2362179319 AreaUnitCmd DeviceDescriptionMsgType 2-2, 3-3;
SG_MUL_VAL_ 2362179319 VolumeUnitCmd DeviceDescriptionMsgType 2-2, 3-3;
SG_MUL_VAL_ 2362179319 MassUnitCmd DeviceDescriptionMsgType 2-2, 3-3;
SG_MUL_VAL_ 2362179319 DateFormatCmd DeviceDescriptionMsgType 2-2, 3-3;
SG_MUL_VAL_ 2362179319 DecimalSymbolCmd DeviceDescriptionMsgType 2-2, 3-3;
SG_MUL_VAL_ 2362179319 TimeFormatCmd DeviceDescriptionMsgType 2-2, 3-3;
SG_MUL_VAL_ 2362179319 LanguageCodeCmd DeviceDescriptionMsgType 2-2, 3-3;
SG_MUL_VAL_ 2362179319 StructureLabel DeviceDescriptionMsgType 1-1;
SG_MUL_VAL_ 2362179319 DeviceDescriptionMsgType Command 1-1;
SG_MUL_VAL_ 2362179319 VersionNumberISO11783Part10 TechnicalDataMsgType 1-1;
SG_MUL_VAL_ 2362179319 TechnicalDataMsgType Command 0-0;
SG_MUL_VAL_ 2362179319 ElementNumber Command 2-8;
SG_MUL_VAL_ 2362179319 DDI Command 2-8;
SG_MUL_VAL_ 2362179319 MinMassPerAreaAppRate DDI 152-152;
SG_MUL_VAL_ 2362179319 DataDictionaryVersion DDI 0-0;
SG_MUL_VAL_ 2362179319 RequestDefaultProcessData DDI 57343-57343;
SG_MUL_VAL_ 2362179319 AreaPerTimeCapacity DDI 151-151;
SG_MUL_VAL_ 2362179319 FuelConsumptionPerArea DDI 150-150;
SG_MUL_VAL_ 2362179319 FuelConsumptionPerTime DDI 149-149;
SG_MUL_VAL_ 2362179319 TotalFuelConsumption DDI 148-148;
SG_MUL_VAL_ 2362179319 LogCount DDI 147-147;
SG_MUL_VAL_ 2362179319 PitchAngle DDI 146-146;
SG_MUL_VAL_ 2362179319 RollAngle DDI 145-145;
SG_MUL_VAL_ 2362179319 YawAngle DDI 144-144;
SG_MUL_VAL_ 2362179319 ActualValueTimeLatency DDI 143-143;
SG_MUL_VAL_ 2362179319 SetpointTimeLatency DDI 142-142;
SG_MUL_VAL_ 2362179319 WorkState DDI 141-141;
SG_MUL_VAL_ 2362179319 PercentageAppRateSetpoint DDI 140-140;
SG_MUL_VAL_ 2362179319 DeviceCountCapacity DDI 139-139;
SG_MUL_VAL_ 2362179319 DeviceMassCapacity DDI 138-138;
SG_MUL_VAL_ 2362179319 DeviceVolumeCapacity DDI 137-137;
SG_MUL_VAL_ 2362179319 DeviceElementOffsetZ DDI 136-136;
SG_MUL_VAL_ 2362179319 DeviceElementOffsetY DDI 135-135;
SG_MUL_VAL_ 2362179319 DeviceElementOffsetX DDI 134-134;
SG_MUL_VAL_ 2362179319 AuxiliaryValveInvertPorts DDI 133-133;
SG_MUL_VAL_ 2362179319 AuxiliaryValveProgressivRetract DDI 132-132;
SG_MUL_VAL_ 2362179319 AuxiliaryValveProgressivExtend DDI 131-131;
SG_MUL_VAL_ 2362179319 AuxiliaryValveFloatThreshold DDI 130-130;
SG_MUL_VAL_ 2362179319 AuxiliaryValveRampRetractDown DDI 129-129;
SG_MUL_VAL_ 2362179319 AuxiliaryValveRampRetractUp DDI 128-128;
SG_MUL_VAL_ 2362179319 AuxiliaryValveRampExtendDown DDI 127-127;
SG_MUL_VAL_ 2362179319 AuxiliaryValveScalingRetract DDI 125-125;
SG_MUL_VAL_ 2362179319 AuxiliaryValveScalingExtend DDI 124-124;
SG_MUL_VAL_ 2362179319 AuxiliaryRampExtendUp DDI 126-126;
SG_MUL_VAL_ 2362179319 AppRateVolumePerArea_Set DDI 1-1;
SG_MUL_VAL_ 2362179319 AppRateVolumePerArea_Act DDI 2-2;
SG_MUL_VAL_ 2362179319 AppRateVolumePerArea_Def DDI 3-3;
SG_MUL_VAL_ 2362179319 AppRateVolumePerArea_Min DDI 4-4;
SG_MUL_VAL_ 2362179319 AppRateVolumePerArea_Max DDI 5-5;
SG_MUL_VAL_ 2362179319 AppRateMassPerArea_Set DDI 6-6;
SG_MUL_VAL_ 2362179319 AppRateMassPerArea_Act DDI 7-7;
SG_MUL_VAL_ 2362179319 AppRateMassPerArea_Def DDI 8-8;
SG_MUL_VAL_ 2362179319 AppRateMassPerArea_Min DDI 9-9;
SG_MUL_VAL_ 2362179319 AppRateMassPerArea_Max DDI 10-10;
SG_MUL_VAL_ 2362179319 AppRateCountPerArea_Set DDI 11-11;
SG_MUL_VAL_ 2362179319 AppRateCountPerArea_Act DDI 12-12;
SG_MUL_VAL_ 2362179319 AppRateCountPerArea_Def DDI 13-13;
SG_MUL_VAL_ 2362179319 AppRateCountPerArea_Min DDI 14-14;
SG_MUL_VAL_ 2362179319 AppRateCountPerArea_Max DDI 15-15;
SG_MUL_VAL_ 2362179319 SetAppRateDistance_Set DDI 16-16;
SG_MUL_VAL_ 2362179319 AppRateDistance_Act DDI 17-17;
SG_MUL_VAL_ 2362179319 AppRateDistance_Def DDI 18-18;
SG_MUL_VAL_ 2362179319 AppRateDistance_Min DDI 19-19;
SG_MUL_VAL_ 2362179319 AppRateDistance_Max DDI 20-20;
SG_MUL_VAL_ 2362179319 AppRateVolumePerVolume_Set DDI 21-21;
SG_MUL_VAL_ 2362179319 AppRateVolumePerVolume_Act DDI 22-22;
SG_MUL_VAL_ 2362179319 AppRateVolumePerVolume_Def DDI 23-23;
SG_MUL_VAL_ 2362179319 AppRateVolumePerVolume_Min DDI 24-24;
SG_MUL_VAL_ 2362179319 AppRateVolumePerVolume_Max DDI 25-25;
SG_MUL_VAL_ 2362179319 AppRateMassPerMass_Set DDI 26-26;
SG_MUL_VAL_ 2362179319 AppRateMassPerMass_Act DDI 27-27;
SG_MUL_VAL_ 2362179319 AppRateMassPerMass_Def DDI 28-28;
SG_MUL_VAL_ 2362179319 AppRateMassPerMass_Min DDI 29-29;
SG_MUL_VAL_ 2362179319 AppRateMassPerMass_Max DDI 30-30;
SG_MUL_VAL_ 2362179319 AppRateVolumePerMass_Set DDI 31-31;
SG_MUL_VAL_ 2362179319 AppRateVolumePerMass_Act DDI 32-32;
SG_MUL_VAL_ 2362179319 AppRateVolumePerMass_Def DDI 33-33;
SG_MUL_VAL_ 2362179319 AppRateVolumePerMass_Min DDI 34-34;
SG_MUL_VAL_ 2362179319 AppRateVolumePerMass_Max DDI 35-35;
SG_MUL_VAL_ 2362179319 AppRateVolumePerTime_Set DDI 36-36;
SG_MUL_VAL_ 2362179319 AppRateVolumePerTime_Act DDI 37-37;
SG_MUL_VAL_ 2362179319 AppRateVolumePerTime_Def DDI 38-38;
SG_MUL_VAL_ 2362179319 AppRateVolumePerTime_Min DDI 39-39;
SG_MUL_VAL_ 2362179319 AppRateVolumePerTime_Max DDI 40-40;
SG_MUL_VAL_ 2362179319 AppRateMassPerTime_Set DDI 41-41;
SG_MUL_VAL_ 2362179319 AppRateMassPerTime_Act DDI 42-42;
SG_MUL_VAL_ 2362179319 AppRateMassPerTime_Def DDI 43-43;
SG_MUL_VAL_ 2362179319 AppRateMassPerTime_Min DDI 44-44;
SG_MUL_VAL_ 2362179319 AppRateMassPerTime_Max DDI 45-45;
SG_MUL_VAL_ 2362179319 AppRateCountPerTime_Set DDI 46-46;
SG_MUL_VAL_ 2362179319 AppRateCountPerTime_Act DDI 47-47;
SG_MUL_VAL_ 2362179319 AppRateCountPerTime_Def DDI 48-48;
SG_MUL_VAL_ 2362179319 AppRateCountPerTime_Min DDI 49-49;
SG_MUL_VAL_ 2362179319 AppRateCountPerTime_Max DDI 50-50;
SG_MUL_VAL_ 2362179319 SetTillageDepth_Set DDI 51-51;
SG_MUL_VAL_ 2362179319 TillageDepth_Act DDI 52-52;
SG_MUL_VAL_ 2362179319 TillageDepth_Def DDI 53-53;
SG_MUL_VAL_ 2362179319 TillageDepth_Min DDI 54-54;
SG_MUL_VAL_ 2362179319 TillageDepth_Max DDI 55-55;
SG_MUL_VAL_ 2362179319 SeedingDeph_Set DDI 56-56;
SG_MUL_VAL_ 2362179319 SeedingDeph_Act DDI 57-57;
SG_MUL_VAL_ 2362179319 SeedingDeph_Def DDI 58-58;
SG_MUL_VAL_ 2362179319 SeedingDeph_Min DDI 59-59;
SG_MUL_VAL_ 2362179319 SeedingDeph_Max DDI 60-60;
SG_MUL_VAL_ 2362179319 WorkingHeight_Set DDI 61-61;
SG_MUL_VAL_ 2362179319 WorkingHeight_Act DDI 62-62;
SG_MUL_VAL_ 2362179319 WorkingHeight_Def DDI 63-63;
SG_MUL_VAL_ 2362179319 WorkingHeight_Min DDI 64-64;
SG_MUL_VAL_ 2362179319 WorkingHeight_Max DDI 65-65;
SG_MUL_VAL_ 2362179319 WorkingWidth_Set DDI 66-66;
SG_MUL_VAL_ 2362179319 WorkingWidth_Act DDI 67-67;
SG_MUL_VAL_ 2362179319 WorkingWidth_Def DDI 68-68;
SG_MUL_VAL_ 2362179319 WorkingWidth_Min DDI 69-69;
SG_MUL_VAL_ 2362179319 WorkingWidth_Max DDI 70-70;
SG_MUL_VAL_ 2362179319 ContentAsVolume_Set DDI 71-71;
SG_MUL_VAL_ 2362179319 ContentAsVolume_Act DDI 72-72;
SG_MUL_VAL_ 2362179319 ContentAsVolume_Max DDI 73-73;
SG_MUL_VAL_ 2362179319 ContentAsMass_Set DDI 74-74;
SG_MUL_VAL_ 2362179319 ContentAsMass_Act DDI 75-75;
SG_MUL_VAL_ 2362179319 ContentAsMass_Max DDI 76-76;
SG_MUL_VAL_ 2362179319 ContentAsCount_Set DDI 77-77;
SG_MUL_VAL_ 2362179319 ContentAsCount_Act DDI 78-78;
SG_MUL_VAL_ 2362179319 ContentAsCount_Max DDI 79-79;
SG_MUL_VAL_ 2362179319 AccumulatedAppAsVolume DDI 80-80;
SG_MUL_VAL_ 2362179319 AccumulatedAppAsMass DDI 81-81;
SG_MUL_VAL_ 2362179319 AccumulatedAppAsCount DDI 82-82;
SG_MUL_VAL_ 2362179319 YieldVolumePerArea DDI 83-83;
SG_MUL_VAL_ 2362179319 YieldMassPerArea DDI 84-84;
SG_MUL_VAL_ 2362179319 YieldCountPerArea DDI 85-85;
SG_MUL_VAL_ 2362179319 YieldVolumePerTime DDI 86-86;
SG_MUL_VAL_ 2362179319 YieldMassPerTime DDI 87-87;
SG_MUL_VAL_ 2362179319 YieldCountPerTime DDI 88-88;
SG_MUL_VAL_ 2362179319 AccumulatedYieldAsVolume DDI 89-89;
SG_MUL_VAL_ 2362179319 AccumulatedYieldAsMass DDI 90-90;
SG_MUL_VAL_ 2362179319 AccumulatedYieldAsCount DDI 91-91;
SG_MUL_VAL_ 2362179319 CropYieldLossVolumePerArea DDI 92-92;
SG_MUL_VAL_ 2362179319 CropYieldLossMassPerArea DDI 93-93;
SG_MUL_VAL_ 2362179319 CropYieldLossCountPerArea DDI 94-94;
SG_MUL_VAL_ 2362179319 CropYieldLossVolumePerTime DDI 95-95;
SG_MUL_VAL_ 2362179319 CropYieldLossMassPerTime DDI 96-96;
SG_MUL_VAL_ 2362179319 CropYieldLossCountPerTime DDI 97-97;
SG_MUL_VAL_ 2362179319 CropYieldLoss DDI 98-98;
SG_MUL_VAL_ 2362179319 MoistureInCropYield DDI 99-99;
SG_MUL_VAL_ 2362179319 DirtMaterialInCropYield DDI 100-100;
SG_MUL_VAL_ 2362179319 BaleWidth_Set DDI 101-101;
SG_MUL_VAL_ 2362179319 BaleWidth_Act DDI 102-102;
SG_MUL_VAL_ 2362179319 BaleWidth_Def DDI 103-103;
SG_MUL_VAL_ 2362179319 BaleWidth_Min DDI 104-104;
SG_MUL_VAL_ 2362179319 BaleWidth_Max DDI 105-105;
SG_MUL_VAL_ 2362179319 BaleHeight_Set DDI 106-106;
SG_MUL_VAL_ 2362179319 BaleHeight_Act DDI 107-107;
SG_MUL_VAL_ 2362179319 BaleHeight_Def DDI 108-108;
SG_MUL_VAL_ 2362179319 BaleHeight_Min DDI 109-109;
SG_MUL_VAL_ 2362179319 BaleHeight_Max DDI 110-110;
SG_MUL_VAL_ 2362179319 BaleSize_Set DDI 111-111;
SG_MUL_VAL_ 2362179319 BaleSize_Act DDI 112-112;
SG_MUL_VAL_ 2362179319 BaleSize_Def DDI 113-113;
SG_MUL_VAL_ 2362179319 BaleSize_Min DDI 114-114;
SG_MUL_VAL_ 2362179319 BaleSize_Max DDI 115-115;
SG_MUL_VAL_ 2362179319 AccumulatedArea DDI 116-116;
SG_MUL_VAL_ 2362179319 AccumulatedDistanceInWork DDI 117-117;
SG_MUL_VAL_ 2362179319 AccumulatedDistanceOutWork DDI 118-118;
SG_MUL_VAL_ 2362179319 AccumulatedTimeInWork DDI 119-119;
SG_MUL_VAL_ 2362179319 AccumulatedTimeOutWork DDI 120-120;
SG_MUL_VAL_ 2362179319 PrdoucDensityMassPerArea DDI 121-121;
SG_MUL_VAL_ 2362179319 PrdoucDensityMassPerCount DDI 122-122;
SG_MUL_VAL_ 2362179319 PrdoucDensityVolumePerCount DDI 123-123;
